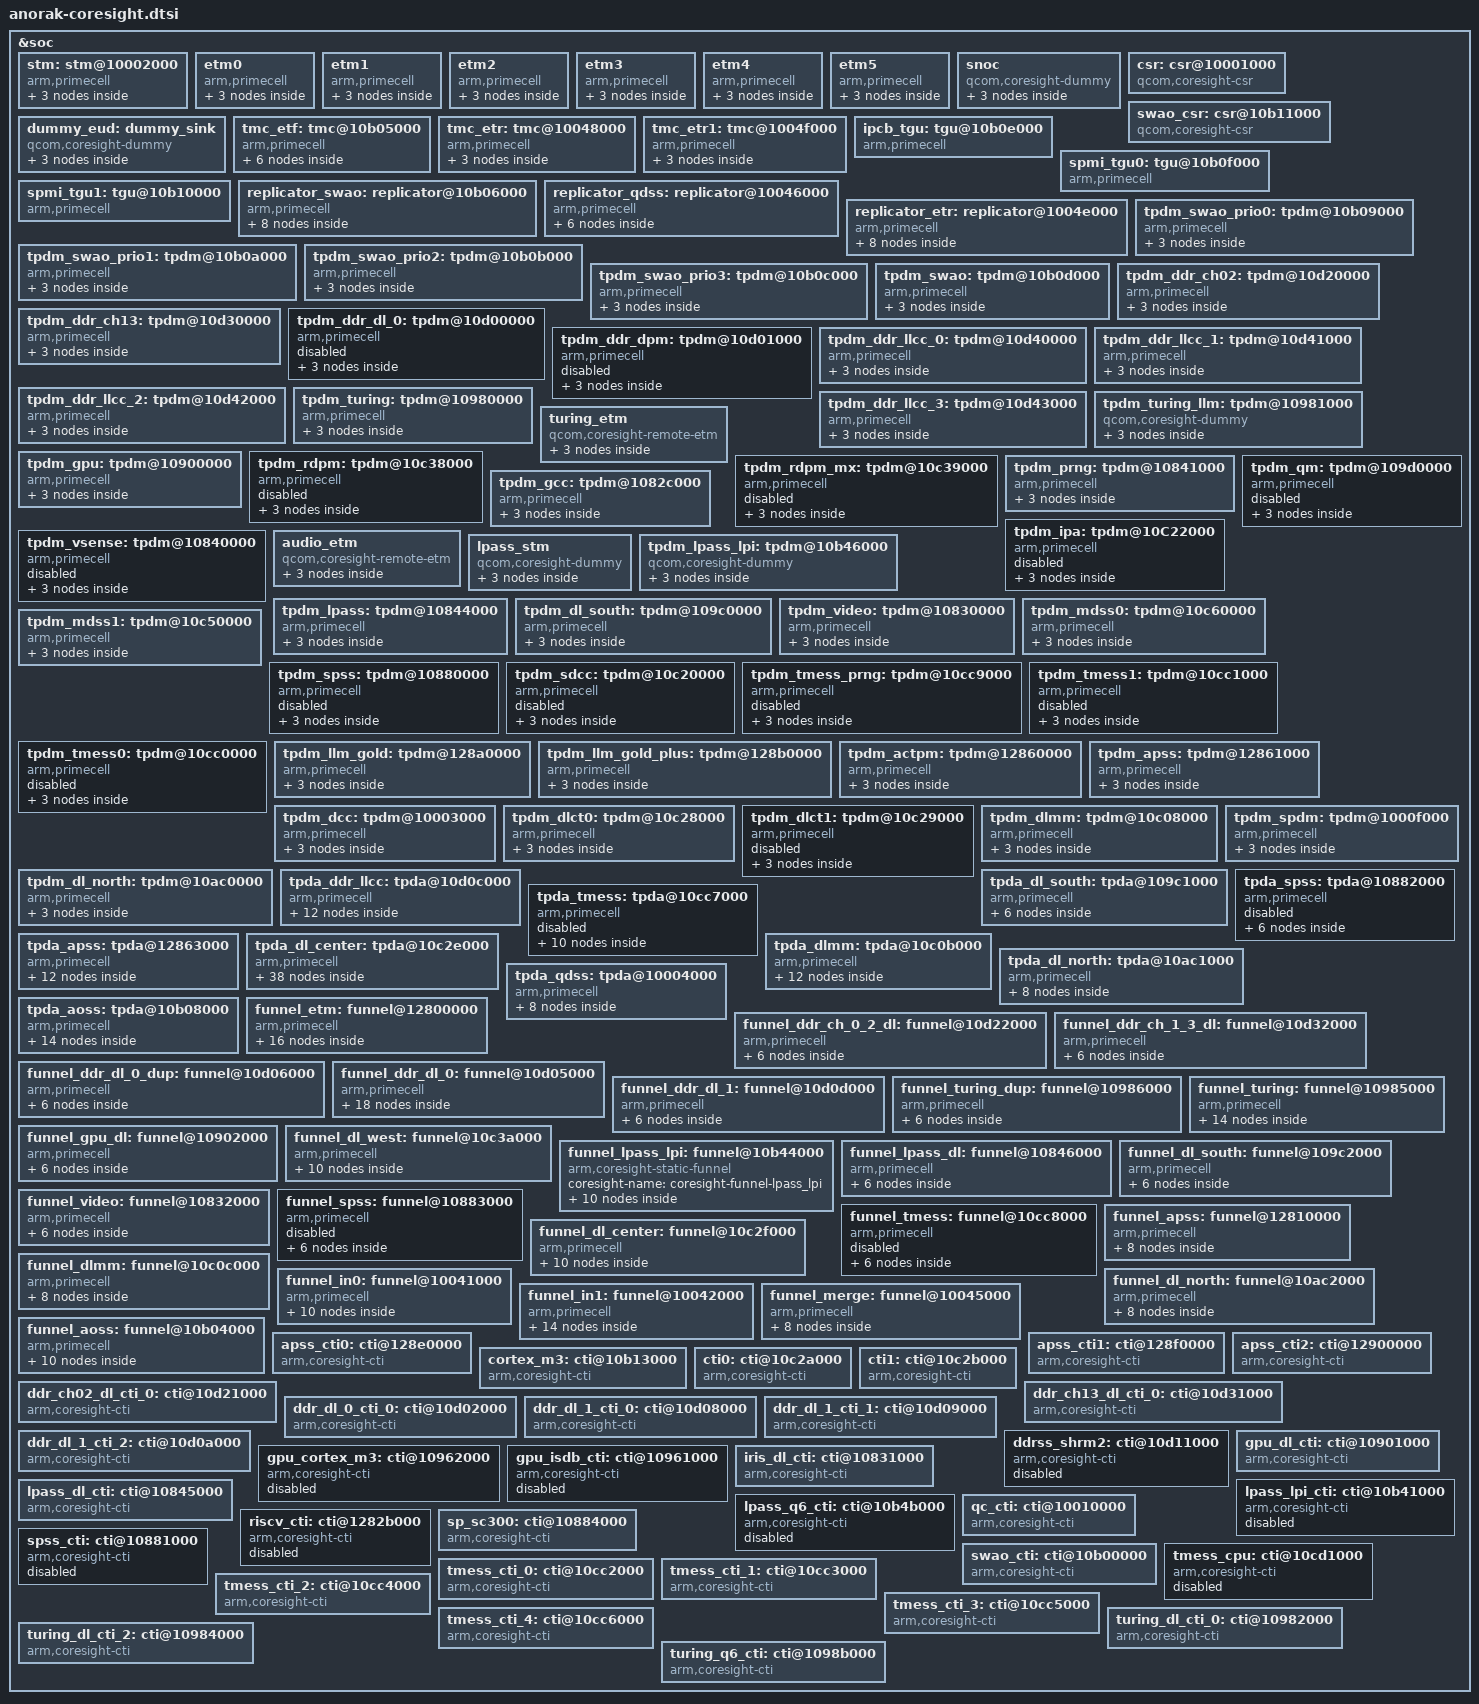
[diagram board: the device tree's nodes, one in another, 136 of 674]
&soc {

	stm: stm@10002000 {
		compatible = "arm,primecell";
		arm,primecell-periphid = <0x000bb962>;
		reg = <0x10002000 0x1000>,
			<0x16280000 0x180000>;
		reg-names = "stm-base", "stm-stimulus-base";

		atid = <16>;
		coresight-name = "coresight-stm";

		clocks = <&aoss_qmp>;
		clock-names = "apb_pclk";

		out-ports {
			port {
				stm_out_funnel_in0: endpoint {
					remote-endpoint =
					<&funnel_in0_in_stm>;
				};
			};
		};
	};

	etm0 {
		compatible = "arm,primecell";
		arm,primecell-periphid = <0x000bb95d>;
		reg = <0x12040000 0x1000>;
		cpu = <&CPU0>;

		coresight-name = "coresight-etm0";
		qcom,skip-power-up;

		clocks = <&aoss_qmp>;
		clock-names = "apb_pclk";
		atid = <1>;
		out-ports {
			port {
				ete0_out_funnel_ete: endpoint {
				remote-endpoint = <&funnel_ete_in_ete0>;
				};
			};
		};
	};

	etm1 {
		compatible = "arm,primecell";
		arm,primecell-periphid = <0x000bb95d>;
		reg = <0x12140000 0x1000>;
		cpu = <&CPU1>;

		coresight-name = "coresight-etm1";
		qcom,skip-power-up;

		clocks = <&aoss_qmp>;
		clock-names = "apb_pclk";
		atid = <2>;
		out-ports {
			port {
				ete1_out_funnel_ete: endpoint {
				remote-endpoint = <&funnel_ete_in_ete1>;
				};
			};
		};
	};

	etm2 {
		compatible = "arm,primecell";
		arm,primecell-periphid = <0x000bb95d>;
		reg = <0x12240000 0x1000>;
		cpu = <&CPU2>;

		coresight-name = "coresight-etm2";
		qcom,skip-power-up;

		clocks = <&aoss_qmp>;
		clock-names = "apb_pclk";
		atid = <3>;
		out-ports {
			port {
				ete2_out_funnel_ete: endpoint {
				remote-endpoint = <&funnel_ete_in_ete2>;
				};
			};
		};
	};

	etm3 {
		compatible = "arm,primecell";
		arm,primecell-periphid = <0x000bb95d>;
		reg = <0x12340000 0x1000>;
		cpu = <&CPU3>;

		coresight-name = "coresight-etm3";
		qcom,skip-power-up;

		clocks = <&aoss_qmp>;
		clock-names = "apb_pclk";
		atid = <4>;
		out-ports {
			port {
				ete3_out_funnel_ete: endpoint {
				remote-endpoint = <&funnel_ete_in_ete3>;
				};
			};
		};
	};

	etm4 {
		compatible = "arm,primecell";
		arm,primecell-periphid = <0x000bb95d>;
		reg = <0x12440000 0x1000>;
		cpu = <&CPU4>;

		coresight-name = "coresight-etm4";
		qcom,skip-power-up;

		clocks = <&aoss_qmp>;
		clock-names = "apb_pclk";
		atid = <5>;
		out-ports {
			port {
				ete4_out_funnel_ete: endpoint {
				remote-endpoint = <&funnel_ete_in_ete4>;
				};
			};
		};
	};

	etm5 {
		compatible = "arm,primecell";
		arm,primecell-periphid = <0x000bb95d>;
		reg = <0x12540000 0x1000>;
		cpu = <&CPU5>;

		coresight-name = "coresight-etm5";
		qcom,skip-power-up;

		clocks = <&aoss_qmp>;
		clock-names = "apb_pclk";
		atid = <6>;
		out-ports {
			port {
				ete5_out_funnel_ete: endpoint {
				remote-endpoint = <&funnel_ete_in_ete5>;
				};
			};
		};
	};

	snoc: snoc {
		compatible = "qcom,coresight-dummy";
		coresight-name = "coresight-snoc";
		qcom,dummy-source;

		atid = <125>;
		out-ports {
			port {
				snoc_out_funnel_in0: endpoint {
					remote-endpoint =
					<&funnel_in0_in_snoc>;
				};
			};
		};
	};

	csr: csr@10001000 {
		compatible = "qcom,coresight-csr";
		reg = <0x10001000 0x1000>;
		reg-names = "csr-base";

		coresight-name = "coresight-csr";
		qcom,usb-bam-support;
		qcom,hwctrl-set-support;
		qcom,set-byte-cntr-support;

		qcom,blk-size = <1>;
	};

	swao_csr: csr@10b11000 {
		compatible = "qcom,coresight-csr";

		reg = <0x10b11000 0x1000>,
		      <0x10b110f8 0x50>;
		reg-names = "csr-base", "msr-base";

		coresight-name = "coresight-swao-csr";
		qcom,timestamp-support;
		qcom,msr-support;
		qcom,blk-size = <1>;

		clocks = <&aoss_qmp>;
		clock-names = "apb_pclk";
	};

	dummy_eud: dummy_sink {
		compatible = "qcom,coresight-dummy";

		coresight-name = "coresight-eud";

		qcom,dummy-sink;
		in-ports {
			port {
				eud_in_replicator_swao: endpoint {
					remote-endpoint =
						<&replicator_swao_out_eud>;
				};
			};
		};
	};

	tmc_etf: tmc@10b05000 {
		compatible = "arm,primecell";
		arm,primecell-periphid = <0x000bb961>;
		reg = <0x10b05000 0x1000>;
		reg-names = "tmc-base";

		coresight-name = "coresight-tmc-etf";

		clocks = <&aoss_qmp>;
		clock-names = "apb_pclk";

		in-ports {
			port {
				tmc_etf_in_funnel_aoss: endpoint {
					remote-endpoint =
					<&funnel_aoss_out_tmc_etf>;
				};
			};
		};

		out-ports {
			port {
				tmc_etf_out_replicator_swao: endpoint {
					remote-endpoint =
					<&replicator_swao_in_tmc_etf>;
				};
			};
		};
	};

	tmc_etr: tmc@10048000 {
		compatible = "arm,primecell";
		arm,primecell-periphid = <0x000bb961>;
		reg = <0x10048000 0x1000>,
			<0x10064000 0x16000>;
		reg-names = "tmc-base", "bam-base";

		qcom,iommu-dma = "bypass";
		iommus = <&apps_smmu 0x04c0 0>,
			<&apps_smmu 0x04a0 0>;

		qcom,iommu-dma-addr-pool = <0x0 0xffc00000>;

		qcom,sw-usb;
		dma-coherent;
		coresight-name = "coresight-tmc-etr";

		coresight-csr = <&csr>;
		csr-atid-offset = <0xf8>;
		csr-irqctrl-offset = <0x6c>;
		byte-cntr-name = "byte-cntr";
		byte-cntr-class-name = "coresight-tmc-etr-stream";

		interrupts = <GIC_SPI 270 IRQ_TYPE_EDGE_RISING>;
		interrupt-names = "byte-cntr-irq";

		arm,scatter-gather;
		clocks = <&aoss_qmp>;
		clock-names = "apb_pclk";

		in-ports {
			port {
				tmc_etr_in_replicator_etr: endpoint {
					remote-endpoint =
					<&replicator_etr_out_tmc_etr>;
				};
			};
		};
	};

	tmc_etr1: tmc@1004f000 {
		compatible = "arm,primecell";
		arm,primecell-periphid = <0x000bb961>;
		reg = <0x1004f000 0x1000>;
		reg-names = "tmc-base";

		coresight-name = "coresight-tmc-etr1";

		iommus = <&apps_smmu 0x04e0 0>;
		qcom,iommu-dma-addr-pool = <0x0 0xffc00000>;

		dma-coherent;
		coresight-csr = <&csr>;
		csr-atid-offset = <0x108>;
		csr-irqctrl-offset = <0x70>;
		byte-cntr-name = "byte-cntr1";
		byte-cntr-class-name = "coresight-tmc-etr1-stream";

		interrupts = <GIC_SPI 269 IRQ_TYPE_EDGE_RISING>;
		interrupt-names = "byte-cntr-irq";

		arm,scatter-gather;
		clocks = <&aoss_qmp>;
		clock-names = "apb_pclk";

		in-ports {
			port {
				tmc_etr1_in_replicator_etr: endpoint {
					remote-endpoint =
					<&replicator_etr_out_tmc_etr1>;
				};
			};
		};
	};

	ipcb_tgu: tgu@10b0e000 {
		compatible = "arm,primecell";
		arm,primecell-periphid = <0x000bb999>;

		reg = <0x10b0e000 0x1000>;
		reg-names = "tgu-base";

		tgu-steps = <3>;
		tgu-conditions = <4>;
		tgu-regs = <4>;
		tgu-timer-counters = <8>;

		coresight-name = "coresight-tgu-ipcb";
		clocks = <&aoss_qmp>;
		clock-names = "apb_pclk";
	};

	spmi_tgu0: tgu@10b0f000 {
		compatible = "arm,primecell";
		arm,primecell-periphid = <0x000bb999>;

		reg = <0x10b0f000 0x1000>;
		reg-names = "tgu-base";

		tgu-steps = <3>;
		tgu-conditions = <4>;
		tgu-regs = <9>;
		tgu-timer-counters = <8>;

		coresight-name = "coresight-tgu-spmi0";
		clocks = <&aoss_qmp>;
		clock-names = "apb_pclk";
	};

	spmi_tgu1: tgu@10b10000 {
		compatible = "arm,primecell";
		arm,primecell-periphid = <0x000bb999>;

		reg = <0x10b10000 0x1000>;
		reg-names = "tgu-base";

		tgu-steps = <3>;
		tgu-conditions = <4>;
		tgu-regs = <9>;
		tgu-timer-counters = <8>;

		coresight-name = "coresight-tgu-spmi1";
		clocks = <&aoss_qmp>;
		clock-names = "apb_pclk";
	};

	replicator_swao: replicator@10b06000 {
		compatible = "arm,primecell";
		arm,primecell-periphid = <0x000bb909>;
		reg = <0x10b06000 0x1000>;
		reg-names = "replicator-base";

		coresight-name = "coresight-replicator-swao";

		clocks = <&aoss_qmp>;
		clock-names = "apb_pclk";

		in-ports {
			port {
				replicator_swao_in_tmc_etf: endpoint {
					remote-endpoint =
					<&tmc_etf_out_replicator_swao>;
				};
			};
		};

		out-ports {
			#address-cells = <1>;
			#size-cells = <0>;

			port@0 {
				reg = <0>;
				replicator_swao_out_replicator_qdss: endpoint {
					remote-endpoint =
					<&replicator_qdss_in_replicator_swao>;
				};
			};

			port@1 {
				reg = <1>;
				replicator_swao_out_eud: endpoint {
					remote-endpoint =
					  <&eud_in_replicator_swao>;
				};
			};
		};
	};

	replicator_qdss: replicator@10046000 {
		compatible = "arm,primecell";
		arm,primecell-periphid = <0x000bb909>;
		reg = <0x10046000 0x1000>;
		reg-names = "replicator-base";

		coresight-name = "coresight-replicator-qdss";

		clocks = <&aoss_qmp>;
		clock-names = "apb_pclk";

		in-ports {
			port {
				replicator_qdss_in_replicator_swao: endpoint {
					remote-endpoint =
					<&replicator_swao_out_replicator_qdss>;
				};
			};
		};

		out-ports {

			port@0 {
				replicator_qdss_out_replicator_etr: endpoint {
					remote-endpoint =
					<&replicator_etr_in_replicator_qdss>;
				};
			};
		};
	};

	replicator_etr: replicator@1004e000 {
		compatible = "arm,primecell";
		arm,primecell-periphid = <0x000bb909>;
		reg = <0x1004e000 0x1000>;
		reg-names = "replicator-base";

		coresight-name = "coresight-replicator-etr";

		clocks = <&aoss_qmp>;
		clock-names = "apb_pclk";

		in-ports {
			port {
				replicator_etr_in_replicator_qdss: endpoint {
					remote-endpoint =
					<&replicator_qdss_out_replicator_etr>;
				};
			};
		};

		out-ports {
			#address-cells = <1>;
			#size-cells = <0>;

			port@0 {
				reg = <0>;
				replicator_etr_out_tmc_etr: endpoint {
					remote-endpoint =
					<&tmc_etr_in_replicator_etr>;
				};
			};

			port@1 {
				reg = <1>;
				replicator_etr_out_tmc_etr1: endpoint {
					remote-endpoint =
					<&tmc_etr1_in_replicator_etr>;
				};
			};
		};
	};

	tpdm_swao_prio0: tpdm@10b09000 {
		compatible = "arm,primecell";
		arm,primecell-periphid = <0x000bb968>;
		reg = <0x10b09000 0x1000>;
		reg-names = "tpdm-base";

		coresight-name = "coresight-tpdm-swao-prio-0";
		atid = <71>;
		clocks = <&aoss_qmp>;
		clock-names = "apb_pclk";

		out-ports {
			port {
				tpdm_swao_prio0_out_tpda_aoss: endpoint {
					remote-endpoint =
					<&tpda_aoss_in_tpdm_swao_prio0>;
				};
			};
		};
	};

	tpdm_swao_prio1: tpdm@10b0a000 {
		compatible = "arm,primecell";
		arm,primecell-periphid = <0x000bb968>;
		reg = <0x10b0a000 0x1000>;
		reg-names = "tpdm-base";

		coresight-name = "coresight-tpdm-swao-prio-1";
		atid = <71>;
		clocks = <&aoss_qmp>;
		clock-names = "apb_pclk";

		out-ports {
			port {
				tpdm_swao_prio1_out_tpda_aoss: endpoint {
					remote-endpoint =
					<&tpda_aoss_in_tpdm_swao_prio1>;
				};
			};
		};
	};

	tpdm_swao_prio2: tpdm@10b0b000 {
		compatible = "arm,primecell";
		arm,primecell-periphid = <0x000bb968>;
		reg = <0x10b0b000 0x1000>;
		reg-names = "tpdm-base";

		coresight-name = "coresight-tpdm-swao-prio-2";
		atid = <71>;
		clocks = <&aoss_qmp>;
		clock-names = "apb_pclk";

		out-ports {
			port {
				tpdm_swao_prio2_out_tpda_aoss: endpoint {
					remote-endpoint =
					<&tpda_aoss_in_tpdm_swao_prio2>;
				};
			};
		};
	};

	tpdm_swao_prio3: tpdm@10b0c000 {
		compatible = "arm,primecell";
		arm,primecell-periphid = <0x000bb968>;
		reg = <0x10b0c000 0x1000>;
		reg-names = "tpdm-base";

		coresight-name = "coresight-tpdm-swao-prio-3";
		atid = <71>;
		clocks = <&aoss_qmp>;
		clock-names = "apb_pclk";

		out-ports {
			port {
				tpdm_swao_prio3_out_tpda_aoss: endpoint {
					remote-endpoint =
					<&tpda_aoss_in_tpdm_swao_prio3>;
				};
			};
		};
	};

	tpdm_swao: tpdm@10b0d000 {
		compatible = "arm,primecell";
		arm,primecell-periphid = <0x000bb968>;
		reg = <0x10b0d000 0x1000>;
		reg-names = "tpdm-base";

		coresight-name = "coresight-tpdm-swao";
		atid = <71>;
		clocks = <&aoss_qmp>;
		clock-names = "apb_pclk";

		out-ports {
			port {
				tpdm_swao_out_tpda_aoss: endpoint {
					remote-endpoint =
					<&tpda_aoss_in_tpdm_swao>;
				};
			};
		};
	};

	tpdm_ddr_ch02: tpdm@10d20000 {
		compatible = "arm,primecell";
		arm,primecell-periphid = <0x000bb968>;
		reg = <0x10d20000 0x1000>;
		reg-names = "tpdm-base";

		coresight-name = "coresight-tpdm-ddr-ch02";
		atid = <78>;
		clocks = <&aoss_qmp>;
		clock-names = "apb_pclk";

		out-ports {
			port {
				tpdm_ddr_ch_0_2_out_funnel_ddr_ch_0_2_dl: endpoint {
					remote-endpoint =
					<&funnel_ddr_ch_0_2_dl_in_tpdm_ddr_ch_0_2>;
				};
			};
		};
	};

	tpdm_ddr_ch13: tpdm@10d30000 {
		compatible = "arm,primecell";
		arm,primecell-periphid = <0x000bb968>;
		reg = <0x10d30000 0x1000>;
		reg-names = "tpdm-base";

		coresight-name = "coresight-tpdm-ddr-ch13";
		atid = <78>;
		clocks = <&aoss_qmp>;
		clock-names = "apb_pclk";

		out-ports {
			port {
				tpdm_ddr_ch_1_3_out_funnel_ddr_ch_1_3_dl: endpoint {
					remote-endpoint =
					<&funnel_ddr_ch_1_3_dl_in_tpdm_ddr_ch_1_3>;
				};
			};
		};
	};

	tpdm_ddr_dl_0: tpdm@10d00000 {
		compatible = "arm,primecell";
		arm,primecell-periphid = <0x000bb968>;
		reg = <0x10d00000 0x1000>;
		reg-names = "tpdm-base";

		coresight-name = "coresight-tpdm-ddr-dl_0";
		atid = <78>;
		clocks = <&aoss_qmp>;
		clock-names = "apb_pclk";

		status = "disabled";
		qcom,cmb-msr-skip;
		out-ports {
			port {
				tpdm_ddr_dl_0_out_funnel_ddr_dl_0: endpoint {
					remote-endpoint =
					<&funnel_ddr_dl_0_in_tpdm_ddr_dl_0>;
				};
			};
		};
	};

	tpdm_ddr_dpm: tpdm@10d01000 {
		compatible = "arm,primecell";
		arm,primecell-periphid = <0x000bb968>;
		reg = <0x10d01000 0x1000>;
		reg-names = "tpdm-base";

		coresight-name = "coresight-tpdm-ddr-dpm";
		atid = <78>;
		clocks = <&aoss_qmp>;
		clock-names = "apb_pclk";

		status = "disabled";
		qcom,cmb-msr-skip;
		out-ports {
			port {
				tpdm_ddr_dpm_out_funnel_ddr_dl_0: endpoint {
					remote-endpoint =
					<&funnel_ddr_dl_0_in_tpdm_ddr_dpm>;
				};
			};
		};
	};

	tpdm_ddr_llcc_0: tpdm@10d40000 {
		compatible = "arm,primecell";
		arm,primecell-periphid = <0x000bb968>;
		reg = <0x10d40000 0x1000>;
		reg-names = "tpdm-base";

		coresight-name = "coresight-tpdm-ddr-llcc_0";
		atid = <99>;
		clocks = <&aoss_qmp>;
		clock-names = "apb_pclk";

		out-ports {
			port {
				tpdm_ddr_llcc_0_out_tpda_ddr_llcc: endpoint {
					remote-endpoint =
					<&tpda_ddr_llcc_in_tpdm_ddr_llcc_0>;
				};
			};
		};
	};

	tpdm_ddr_llcc_1: tpdm@10d41000 {
		compatible = "arm,primecell";
		arm,primecell-periphid = <0x000bb968>;
		reg = <0x10d41000 0x1000>;
		reg-names = "tpdm-base";

		coresight-name = "coresight-tpdm-ddr-llcc_1";
		atid = <99>;
		clocks = <&aoss_qmp>;
		clock-names = "apb_pclk";

		out-ports {
			port {
				tpdm_ddr_llcc_1_out_tpda_ddr_llcc: endpoint {
					remote-endpoint =
					<&tpda_ddr_llcc_in_tpdm_ddr_llcc_1>;
				};
			};
		};
	};

	tpdm_ddr_llcc_2: tpdm@10d42000 {
		compatible = "arm,primecell";
		arm,primecell-periphid = <0x000bb968>;
		reg = <0x10d42000 0x1000>;
		reg-names = "tpdm-base";

		coresight-name = "coresight-tpdm-ddr-llcc_2";
		atid = <99>;
		clocks = <&aoss_qmp>;
		clock-names = "apb_pclk";

		out-ports {
			port {
				tpdm_ddr_llcc_2_out_tpda_ddr_llcc: endpoint {
					remote-endpoint =
					<&tpda_ddr_llcc_in_tpdm_ddr_llcc_2>;
				};
			};
		};
	};

	tpdm_ddr_llcc_3: tpdm@10d43000 {
		compatible = "arm,primecell";
		arm,primecell-periphid = <0x000bb968>;
		reg = <0x10d43000 0x1000>;
		reg-names = "tpdm-base";

		coresight-name = "coresight-tpdm-ddr-llcc_3";
		atid = <99>;
		clocks = <&aoss_qmp>;
		clock-names = "apb_pclk";

		out-ports {
			port {
				tpdm_ddr_llcc_3_out_tpda_ddr_llcc: endpoint {
					remote-endpoint =
					<&tpda_ddr_llcc_in_tpdm_ddr_llcc_3>;
				};
			};
		};
	};

	tpdm_turing: tpdm@10980000 {
		compatible = "arm,primecell";
		arm,primecell-periphid = <0x000bb968>;
		reg = <0x10980000 0x1000>;
		reg-names = "tpdm-base";

		coresight-name = "coresight-tpdm-turing";
		atid = <78>;
		clocks = <&aoss_qmp>;
		clock-names = "apb_pclk";

		out-ports {
			port {
				tpdm_turing_out_funnel_turing: endpoint {
					remote-endpoint =
					<&funnel_turing_in_tpdm_turing>;
				};
			};
		};
	};

	tpdm_turing_llm: tpdm@10981000 {
		compatible = "qcom,coresight-dummy";
		coresight-name = "coresight-tpdm-turing-llm";
		qcom,dummy-source;

		out-ports {
			port {
				tpdm_turing_llm_out_funnel_turing: endpoint {
					remote-endpoint =
					<&funnel_turing_in_tpdm_turing_llm>;
				};
			};
		};
	};

	turing_etm {
		compatible = "qcom,coresight-remote-etm";

		coresight-name = "coresight-turing-etm0";
		qcom,inst-id = <13>;

		atid = <38 39>;

		out-ports {
			port {
				turing_etm_out_funnel_turing_dup: endpoint {
					remote-endpoint =
						<&funnel_turing_dup_in_turing_etm>;
				};
			};
		};
	};

	tpdm_gpu: tpdm@10900000 {
		compatible = "arm,primecell";
		arm,primecell-periphid = <0x000bb968>;
		reg = <0x10900000 0x1000>;
		reg-names = "tpdm-base";

		coresight-name = "coresight-tpdm-gpu";
		atid = <78>;
		clocks = <&aoss_qmp>;
		clock-names = "apb_pclk";

		out-ports {
			port {
				tpdm_gpu_out_funnel_gpu_dl: endpoint {
					remote-endpoint =
					<&funnel_gpu_dl_in_tpdm_gpu>;
				};
			};
		};
	};

	tpdm_rdpm: tpdm@10c38000 {
		compatible = "arm,primecell";
		arm,primecell-periphid = <0x000bb968>;
		reg = <0x10c38000 0x1000>;
		reg-names = "tpdm-base";

		coresight-name = "coresight-tpdm-rdpm";
		atid = <78>;
		clocks = <&aoss_qmp>;
		clock-names = "apb_pclk";

		status = "disabled";
		out-ports {
			port {
				tpdm_rdpm_out_funnel_dl_west: endpoint {
					remote-endpoint =
					<&funnel_dl_west_in_tpdm_rdpm>;
				};
			};
		};
	};

	tpdm_rdpm_mx: tpdm@10c39000 {
		compatible = "arm,primecell";
		arm,primecell-periphid = <0x000bb968>;
		reg = <0x10c39000 0x1000>;
		reg-names = "tpdm-base";

		coresight-name = "coresight-tpdm-rdpm-mx";
		atid = <78>;
		clocks = <&aoss_qmp>;
		clock-names = "apb_pclk";
		qcom,cmb-msr-skip;

		status = "disabled";
		out-ports {
			port {
				tpdm_rdpm_mx_out_funnel_dl_west: endpoint {
					remote-endpoint =
					<&funnel_dl_west_in_tpdm_rdpm_mx>;
				};
			};
		};
	};

	tpdm_prng: tpdm@10841000 {
		compatible = "arm,primecell";
		arm,primecell-periphid = <0x000bb968>;
		reg = <0x10841000 0x1000>;
		reg-names = "tpdm-base";

		coresight-name = "coresight-tpdm-prng";
		atid = <78>;
		clocks = <&aoss_qmp>;
		clock-names = "apb_pclk";

		out-ports {
			port {
				tpdm_prng_out_tpda_dl_center: endpoint {
					remote-endpoint =
					<&tpda_dl_center_in_tpdm_prng>;
				};
			};
		};
	};

	tpdm_qm: tpdm@109d0000 {
		compatible = "arm,primecell";
		arm,primecell-periphid = <0x000bb968>;
		reg = <0x109d0000 0x1000>;
		reg-names = "tpdm-base";

		coresight-name = "coresight-tpdm-qm";
		atid = <78>;
		clocks = <&aoss_qmp>;
		clock-names = "apb_pclk";

		status = "disabled";
		out-ports {
			port {
				tpdm_qm_out_tpda_dl_center: endpoint {
					remote-endpoint =
					<&tpda_dl_center_in_tpdm_qm>;
				};
			};
		};
	};

	tpdm_gcc: tpdm@1082c000 {
		compatible = "arm,primecell";
		arm,primecell-periphid = <0x000bb968>;
		reg = <0x1082c000 0x1000>;
		reg-names = "tpdm-base";

		coresight-name = "coresight-tpdm-gcc";
		atid = <78>;
		clocks = <&aoss_qmp>;
		clock-names = "apb_pclk";

		out-ports {
			port {
				tpdm_gcc_out_tpda_dl_center: endpoint {
					remote-endpoint =
					<&tpda_dl_center_in_tpdm_gcc>;
				};
			};
		};
	};

	tpdm_vsense: tpdm@10840000 {
		compatible = "arm,primecell";
		arm,primecell-periphid = <0x000bb968>;
		reg = <0x10840000 0x1000>;
		reg-names = "tpdm-base";

		coresight-name = "coresight-tpdm-vsense";
		atid = <78>;
		clocks = <&aoss_qmp>;
		clock-names = "apb_pclk";

		status = "disabled";
		out-ports {
			port {
				tpdm_vsense_out_tpda_dl_center: endpoint {
					remote-endpoint =
					<&tpda_dl_center_in_tpdm_vsense>;
				};
			};
		};
	};

	tpdm_ipa: tpdm@10C22000 {
		compatible = "arm,primecell";
		arm,primecell-periphid = <0x000bb968>;
		reg = <0x10C22000 0x1000>;
		reg-names = "tpdm-base";

		coresight-name = "coresight-tpdm-ipa";
		atid = <78>;
		clocks = <&aoss_qmp>;
		clock-names = "apb_pclk";
		qcom,cmb-msr-skip;

		status = "disabled";
		out-ports {
			port {
				tpdm_ipa_out_tpda_dl_center: endpoint {
					remote-endpoint =
					<&tpda_dl_center_in_tpdm_ipa>;
				};
			};
		};
	};

	audio_etm {
		compatible = "qcom,coresight-remote-etm";

		coresight-name = "coresight-audio-etm0";
		qcom,inst-id = <5>;

		atid = <40 41>;

		out-ports {
			port {
				audio_etm_out_funnel_lpass_lpi: endpoint {
					remote-endpoint =
						<&funnel_lpass_lpi_in_audio_etm>;
				};
			};
		};
	};

	lpass_stm: lpass_stm {
		compatible = "qcom,coresight-dummy";
		coresight-name = "coresight-lpass-stm";
		qcom,dummy-source;

		atid = <25>;

		out-ports {
			port {
				lpass_stm_out_funnel_lpass_lpi: endpoint {
					remote-endpoint =
					<&funnel_lpass_lpi_in_lpass_stm>;
				};
			};
		};
	};

	tpdm_lpass_lpi: tpdm@10b46000 {
		compatible = "qcom,coresight-dummy";
		coresight-name = "coresight-tpdm-lpass-lpi";
		qcom,dummy-source;

		atid = <26>;

		out-ports {
			port {
				tpdm_lpass_lpi_out_funnel_lpass_lpi: endpoint {
					remote-endpoint =
					<&funnel_lpass_lpi_in_tpdm_lpass_lpi>;
				};
			};
		};
	};

	tpdm_lpass: tpdm@10844000 {
		compatible = "arm,primecell";
		arm,primecell-periphid = <0x000bb968>;
		reg = <0x10844000 0x1000>;
		reg-names = "tpdm-base";

		coresight-name = "coresight-tpdm-lpass";
		atid = <78>;
		clocks = <&aoss_qmp>;
		clock-names = "apb_pclk";

		out-ports {
			port {
				tpdm_lpass_out_funnel_lpass_dl: endpoint {
					remote-endpoint =
					<&funnel_lpass_dl_in_tpdm_lpass>;
				};
			};
		};
	};

	tpdm_dl_south: tpdm@109c0000 {
		compatible = "arm,primecell";
		arm,primecell-periphid = <0x000bb968>;
		reg = <0x109c0000 0x1000>;
		reg-names = "tpdm-base";

		coresight-name = "coresight-tpdm-dl-south";
		atid = <75>;
		clocks = <&aoss_qmp>;
		clock-names = "apb_pclk";

		out-ports {
			port {
				tpdm_dl_south_out_tpda_dl_south: endpoint {
					remote-endpoint =
					<&tpda_dl_south_in_tpdm_dl_south>;
				};
			};
		};
	};

	tpdm_video: tpdm@10830000 {
		compatible = "arm,primecell";
		arm,primecell-periphid = <0x000bb968>;
		reg = <0x10830000 0x1000>;
		reg-names = "tpdm-base";

		coresight-name = "coresight-tpdm-video";
		atid = <81>;
		clocks = <&aoss_qmp>;
		clock-names = "apb_pclk";

		out-ports {
			port {
				tpdm_video_out_funnel_video: endpoint {
					remote-endpoint =
					<&funnel_video_in_tpdm_video>;
				};
			};
		};
	};

	tpdm_mdss0: tpdm@10c60000 {
		compatible = "arm,primecell";
		arm,primecell-periphid = <0x000bb968>;
		reg = <0x10c60000 0x1000>;
		reg-names = "tpdm-base";

		coresight-name = "coresight-tpdm-mdss0";
		atid = <81>;
		clocks = <&aoss_qmp>;
		clock-names = "apb_pclk";

		out-ports {
			port {
				tpdm_mdss0_out_tpda_dlmm: endpoint {
					remote-endpoint =
					<&tpda_dlmm_in_tpdm_mdss0>;
				};
			};
		};
	};

	tpdm_mdss1: tpdm@10c50000 {
		compatible = "arm,primecell";
		arm,primecell-periphid = <0x000bb968>;
		reg = <0x10c50000 0x1000>;
		reg-names = "tpdm-base";

		coresight-name = "coresight-tpdm-mdss1";
		atid = <81>;
		clocks = <&aoss_qmp>;
		clock-names = "apb_pclk";

		out-ports {
			port {
				tpdm_mdss1_out_tpda_dlmm: endpoint {
					remote-endpoint =
					<&tpda_dlmm_in_tpdm_mdss1>;
				};
			};
		};
	};

	tpdm_spss: tpdm@10880000 {
		compatible = "arm,primecell";
		arm,primecell-periphid = <0x000bb968>;
		reg = <0x10880000 0x1000>;
		reg-names = "tpdm-base";

		coresight-name = "coresight-tpdm-spss";

		atid = <70>;
		clocks = <&aoss_qmp>;
		clock-names = "apb_pclk";
		status = "disabled";

		out-ports {
			port {
				tpdm_spss_out_tpda_spss: endpoint {
					remote-endpoint =
					<&tpda_spss_in_tpdm_spss>;
				};
			};
		};
	};

	tpdm_sdcc: tpdm@10c20000 {
		compatible = "arm,primecell";
		arm,primecell-periphid = <0x000bb968>;
		reg = <0x10c20000 0x1000>;
		reg-names = "tpdm-base";

		coresight-name = "coresight-tpdm-sdcc";
		atid = <97>;
		clocks = <&aoss_qmp>;
		clock-names = "apb_pclk";
		qcom,cmb-msr-skip;

		status = "disabled";
		out-ports {
			port {
				tpdm_sdcc_out_tpda_dl_north: endpoint {
					remote-endpoint =
					<&tpda_dl_north_in_tpdm_sdcc>;
				};
			};
		};
	};

	tpdm_tmess_prng: tpdm@10cc9000 {
		compatible = "arm,primecell";
		arm,primecell-periphid = <0x000bb968>;
		reg = <0x10cc9000 0x1000>;
		reg-names = "tpdm-base";

		coresight-name = "coresight-tpdm-tmess-prng";
		atid = <85>;
		clocks = <&aoss_qmp>;
		clock-names = "apb_pclk";

		status = "disabled";
		out-ports {
			port {
				tpdm_tmess_prng_out_tpda_tmess: endpoint {
					remote-endpoint =
					<&tpda_tmess_in_tpdm_tmess_prng>;
				};
			};
		};
	};

	tpdm_tmess1: tpdm@10cc1000 {
		compatible = "arm,primecell";
		arm,primecell-periphid = <0x000bb968>;
		reg = <0x10cc1000 0x1000>;
		reg-names = "tpdm-base";

		coresight-name = "coresight-tpdm-tmess1";
		atid = <85>;
		clocks = <&aoss_qmp>;
		clock-names = "apb_pclk";

		status = "disabled";
		out-ports {
			port {
				tpdm_tmess1_out_tpda_tmess: endpoint {
					remote-endpoint =
					<&tpda_tmess_in_tpdm_tmess1>;
				};
			};
		};
	};

	tpdm_tmess0: tpdm@10cc0000 {
		compatible = "arm,primecell";
		arm,primecell-periphid = <0x000bb968>;
		reg = <0x10cc0000 0x1000>;
		reg-names = "tpdm-base";

		coresight-name = "coresight-tpdm-tmess0";
		atid = <85>;
		clocks = <&aoss_qmp>;
		clock-names = "apb_pclk";

		status = "disabled";
		out-ports {
			port {
				tpdm_tmess0_out_tpda_tmess: endpoint {
					remote-endpoint =
					<&tpda_tmess_in_tpdm_tmess0>;
				};
			};
		};
	};

	tpdm_llm_gold: tpdm@128a0000 {
		compatible = "arm,primecell";
		arm,primecell-periphid = <0x000bb968>;
		reg = <0x128a0000 0x1000>;
		reg-names = "tpdm-base";

		coresight-name = "coresight-tpdm-llm-gold";
		atid = <66>;
		clocks = <&aoss_qmp>;
		clock-names = "apb_pclk";

		out-ports {
			port {
				tpdm_llm_gold_out_tpda_apss: endpoint {
					remote-endpoint =
					<&tpda_apss_in_tpdm_llm_gold>;
				};
			};
		};
	};

	tpdm_llm_gold_plus: tpdm@128b0000 {
		compatible = "arm,primecell";
		arm,primecell-periphid = <0x000bb968>;
		reg = <0x128b0000 0x1000>;
		reg-names = "tpdm-base";

		coresight-name = "coresight-tpdm-llm-gold-plus";
		atid = <66>;
		clocks = <&aoss_qmp>;
		clock-names = "apb_pclk";

		out-ports {
			port {
				tpdm_llm_gold_plus_out_tpda_apss: endpoint {
					remote-endpoint =
					<&tpda_apss_in_tpdm_llm_gold_plus>;
				};
			};
		};
	};

	tpdm_actpm: tpdm@12860000 {
		compatible = "arm,primecell";
		arm,primecell-periphid = <0x000bb968>;
		reg = <0x12860000 0x1000>;
		reg-names = "tpdm-base";

		coresight-name = "coresight-tpdm-actpm";
		atid = <66>;
		clocks = <&aoss_qmp>;
		clock-names = "apb_pclk";

		out-ports {
			port {
				tpdm_actpm_out_tpda_apss: endpoint {
					remote-endpoint =
					<&tpda_apss_in_tpdm_actpm>;
				};
			};
		};
	};

	tpdm_apss: tpdm@12861000 {
		compatible = "arm,primecell";
		arm,primecell-periphid = <0x000bb968>;
		reg = <0x12861000 0x1000>;
		reg-names = "tpdm-base";

		coresight-name = "coresight-tpdm-apss";
		atid = <66>;
		clocks = <&aoss_qmp>;
		clock-names = "apb_pclk";

		out-ports {
			port {
				tpdm_apss_out_tpda_apss: endpoint {
					remote-endpoint =
					<&tpda_apss_in_tpdm_apss>;
				};
			};
		};
	};

	tpdm_dcc: tpdm@10003000 {
		compatible = "arm,primecell";
		arm,primecell-periphid = <0x000bb968>;
		reg = <0x10003000 0x1000>;
		reg-names = "tpdm-base";

		coresight-name = "coresight-tpdm-dcc";
		atid = <65>;
		clocks = <&aoss_qmp>;
		clock-names = "apb_pclk";

		qcom,hw-enable-check;
		out-ports {
			port {
				tpdm_dcc_out_tpda_qdss: endpoint {
					remote-endpoint =
					<&tpda_qdss_in_tpdm_dcc>;
				};
			};
		};
	};

	tpdm_dlct0: tpdm@10c28000 {
		compatible = "arm,primecell";
		arm,primecell-periphid = <0x000bb968>;
		reg = <0x10c28000 0x1000>;
		reg-names = "tpdm-base";

		coresight-name = "coresight-tpdm-dlct0";

		clocks = <&aoss_qmp>;
		clock-names = "apb_pclk";
		atid = <78>;

		out-ports {
			port {
				tpdm_dl_ct0_out_tpda_dl_center: endpoint {
					remote-endpoint =
					<&tpda_dl_center_in_tpdm_dl_ct0>;
				};
			};
		};
	};

	tpdm_dlct1: tpdm@10c29000 {
		compatible = "arm,primecell";
		arm,primecell-periphid = <0x000bb968>;
		reg = <0x10c29000 0x1000>;
		reg-names = "tpdm-base";

		coresight-name = "coresight-tpdm-dlct1";
		atid = <78>;
		clocks = <&aoss_qmp>;
		clock-names = "apb_pclk";

		status = "disabled";
		qcom,cmb-msr-skip;
		out-ports {
			port {
				tpdm_dl_ct1_out_tpda_dl_center: endpoint {
					remote-endpoint =
					<&tpda_dl_center_in_tpdm_dl_ct1>;
				};
			};
		};
	};

	tpdm_dlmm: tpdm@10c08000 {
		compatible = "arm,primecell";
		arm,primecell-periphid = <0x000bb968>;
		reg = <0x10c08000 0x1000>;
		reg-names = "tpdm-base";

		coresight-name = "coresight-tpdm-dlmm";

		clocks = <&aoss_qmp>;
		clock-names = "apb_pclk";
		atid = <81>;

		out-ports {
			port {
				tpdm_dlmm_out_tpda_dlmm: endpoint {
					remote-endpoint =
					<&tpda_dlmm_in_tpdm_dlmm>;
				};
			};
		};
	};

	tpdm_dl_north: tpdm@10ac0000 {
		compatible = "arm,primecell";
		arm,primecell-periphid = <0x000bb968>;
		reg = <0x10ac0000 0x1000>;
		reg-names = "tpdm-base";

		coresight-name = "coresight-tpdm-dl-north";
		atid = <97>;
		clocks = <&aoss_qmp>;
		clock-names = "apb_pclk";

		out-ports {
			port {
				tpdm_dl_north_out_tpda_dl_north: endpoint {
					remote-endpoint =
					<&tpda_dl_north_in_tpdm_dl_north>;
				};
			};
		};
	};

	tpdm_spdm: tpdm@1000f000 {
		compatible = "arm,primecell";
		arm,primecell-periphid = <0x000bb968>;
		reg = <0x1000f000 0x1000>;
		reg-names = "tpdm-base";

		coresight-name = "coresight-tpdm-spdm";
		atid = <65>;
		clocks = <&aoss_qmp>;
		clock-names = "apb_pclk";

		out-ports {
			port {
				tpdm_spdm_out_tpda_qdss: endpoint {
					remote-endpoint =
					<&tpda_qdss_in_tpdm_spdm>;
				};
			};
		};
	};

	tpda_ddr_llcc: tpda@10d0c000 {
		compatible = "arm,primecell";
		arm,primecell-periphid = <0x000bb969>;

		reg = <0x10d0c000 0x1000>;
		reg-names = "tpda-base";

		coresight-name = "coresight-tpda-ddr-llcc";

		clocks = <&aoss_qmp>;
		clock-names = "apb_pclk";

		qcom,tpda-atid = <99>;

		qcom,cmb-elem-size = <0 32>,
					<1 32>,
					<2 32>,
					<3 32>;

		in-ports {

			#address-cells = <1>;
			#size-cells = <0>;

			port@0 {
				reg = <0>;
				tpda_ddr_llcc_in_tpdm_ddr_llcc_0: endpoint {
					remote-endpoint =
					<&tpdm_ddr_llcc_0_out_tpda_ddr_llcc>;
				};
			};

			port@1 {
				reg = <1>;
				tpda_ddr_llcc_in_tpdm_ddr_llcc_1: endpoint {
					remote-endpoint =
					<&tpdm_ddr_llcc_1_out_tpda_ddr_llcc>;
				};
			};

			port@2 {
				reg = <2>;
				tpda_ddr_llcc_in_tpdm_ddr_llcc_2: endpoint {
					remote-endpoint =
					<&tpdm_ddr_llcc_2_out_tpda_ddr_llcc>;
				};
			};

			port@3 {
				reg = <3>;
				tpda_ddr_llcc_in_tpdm_ddr_llcc_3: endpoint {
					remote-endpoint =
					<&tpdm_ddr_llcc_3_out_tpda_ddr_llcc>;
				};
			};
		};

		out-ports {

			port {
				tpda_ddr_llcc_out_funnel_ddr_dl_1: endpoint {
					remote-endpoint =
					<&funnel_ddr_dl_1_in_tpda_ddr_llcc>;
				};
			};

		};
	};

	tpda_dl_south: tpda@109c1000 {
		compatible = "arm,primecell";
		arm,primecell-periphid = <0x000bb969>;

		reg = <0x109c1000 0x1000>;
		reg-names = "tpda-base";

		coresight-name = "coresight-tpda-dl_south";

		clocks = <&aoss_qmp>;
		clock-names = "apb_pclk";

		qcom,tpda-atid = <75>;

		qcom,dsb-elem-size = <2 32>;

		in-ports {

			#address-cells = <1>;
			#size-cells = <0>;

			port@2 {
				reg = <2>;
				tpda_dl_south_in_tpdm_dl_south: endpoint {
					remote-endpoint =
					<&tpdm_dl_south_out_tpda_dl_south>;
				};
			};

		};

		out-ports {

			port {
				tpda_dl_south_out_funnel_dl_south: endpoint {
					remote-endpoint =
					<&funnel_dl_south_in_tpda_dl_south>;
				};
			};

		};
	};

	tpda_spss: tpda@10882000 {
		compatible = "arm,primecell";
		arm,primecell-periphid = <0x000bb969>;

		reg = <0x10882000 0x1000>;
		reg-names = "tpda-base";

		coresight-name = "coresight-tpda-spss";

		clocks = <&aoss_qmp>;
		clock-names = "apb_pclk";

		qcom,tpda-atid = <70>;

		qcom,dsb-elem-size = <0 32>;
		qcom,cmb-elem-size = <0 32>;

		status = "disabled";

		in-ports {

			#address-cells = <1>;
			#size-cells = <0>;

			port@0 {
				reg = <0>;
				tpda_spss_in_tpdm_spss: endpoint {
					remote-endpoint =
					<&tpdm_spss_out_tpda_spss>;
				};
			};

		};

		out-ports {

			port {
				tpda_spss_out_funnel_spss: endpoint {
					remote-endpoint =
					<&funnel_spss_in_tpda_spss>;
				};
			};

		};
	};

	tpda_tmess: tpda@10cc7000 {
		compatible = "arm,primecell";
		arm,primecell-periphid = <0x000bb969>;

		reg = <0x10cc7000 0x1000>;
		reg-names = "tpda-base";

		coresight-name = "coresight-tpda-tmess";

		clocks = <&aoss_qmp>;
		clock-names = "apb_pclk";

		qcom,tpda-atid = <85>;

		status = "disabled";
		qcom,dsb-elem-size = <1 32>;
		qcom,cmb-elem-size = <0 32>,
					<1 32>,
					<2 64>;

		in-ports {

			#address-cells = <1>;
			#size-cells = <0>;

			port@0 {
				reg = <0>;
				tpda_tmess_in_tpdm_tmess_prng: endpoint {
					remote-endpoint =
					<&tpdm_tmess_prng_out_tpda_tmess>;
				};
			};

			port@1 {
				reg = <1>;
				tpda_tmess_in_tpdm_tmess1: endpoint {
					remote-endpoint =
					<&tpdm_tmess1_out_tpda_tmess>;
				};
			};

			port@2 {
				reg = <2>;
				tpda_tmess_in_tpdm_tmess0: endpoint {
					remote-endpoint =
					<&tpdm_tmess0_out_tpda_tmess>;
				};
			};
		};

		out-ports {

			port {
				tpda_tmess_out_funnel_tmess: endpoint {
					remote-endpoint =
					<&funnel_tmess_in_tpda_tmess>;
				};
			};
		};
	};

	tpda_apss: tpda@12863000 {
		compatible = "arm,primecell";
		arm,primecell-periphid = <0x000bb969>;

		reg = <0x12863000 0x1000>;
		reg-names = "tpda-base";

		coresight-name = "coresight-tpda-apss";

		clocks = <&aoss_qmp>;
		clock-names = "apb_pclk";

		qcom,tpda-atid = <66>;

		qcom,dsb-elem-size = <4 32>;
		qcom,cmb-elem-size = <0 32>,
					<1 32>,
					<3 64>;

		in-ports {

			#address-cells = <1>;
			#size-cells = <0>;

			port@0 {
				reg = <0>;
				tpda_apss_in_tpdm_llm_gold: endpoint {
					remote-endpoint =
					<&tpdm_llm_gold_out_tpda_apss>;
				};
			};

			port@1 {
				reg = <1>;
				tpda_apss_in_tpdm_llm_gold_plus: endpoint {
					remote-endpoint =
					<&tpdm_llm_gold_plus_out_tpda_apss>;
				};
			};

			port@3 {
				reg = <3>;
				tpda_apss_in_tpdm_actpm: endpoint {
					remote-endpoint =
					<&tpdm_actpm_out_tpda_apss>;
				};
			};

			port@4 {
				reg = <4>;
				tpda_apss_in_tpdm_apss: endpoint {
					remote-endpoint =
					<&tpdm_apss_out_tpda_apss>;
				};
			};
		};

		out-ports {

			port {
				tpda_apss_out_funnel_apss: endpoint {
					remote-endpoint =
					<&funnel_apss_in_tpda_apss>;
				};
			};
		};
	};

	tpda_dl_center: tpda@10c2e000 {
		compatible = "arm,primecell";
		arm,primecell-periphid = <0x000bb969>;

		reg = <0x10c2e000 0x1000>;
		reg-names = "tpda-base";

		coresight-name = "coresight-tpda-dl_center";

		clocks = <&aoss_qmp>;
		clock-names = "apb_pclk";

		qcom,tpda-atid = <78>;

		qcom,dsb-elem-size = <4 32>,
					<5 32>,
					<7 32>,
					<15 32>,
					<17 32>,
					<20 32>,
					<21 32>,
					<26 32>;

		qcom,cmb-elem-size = <7 32>,
					<8 64>,
					<13 64>,
					<14 64>,
					<16 32>,
					<19 32>,
					<22 32>,
					<27 64>;

		in-ports {

			#address-cells = <1>;
			#size-cells = <0>;

			port@4 {
				reg = <4>;
				tpda_dl_center_in_funnel_lpass_dl: endpoint {
					remote-endpoint =
					<&funnel_lpass_dl_out_tpda_dl_center>;
				};
			};

			port@5 {
				reg = <5>;
				tpda_dl_center_5_in_funnel_ddr_dl_0: endpoint {
					remote-endpoint =
					<&funnel_ddr_dl_0_out_tpda_dl_center_5>;
				};
			};

			port@6 {
				reg = <6>;
				tpda_dl_center_6_in_funnel_ddr_dl_0: endpoint {
					remote-endpoint =
					<&funnel_ddr_dl_0_out_tpda_dl_center_6>;
				};
			};

			port@7 {
				reg = <7>;
				tpda_dl_center_7_in_funnel_ddr_dl_0: endpoint {
					remote-endpoint =
					<&funnel_ddr_dl_0_out_tpda_dl_center_7>;
				};
			};

			port@8 {
				reg = <8>;
				tpda_dl_center_8_in_funnel_ddr_dl_0: endpoint {
					remote-endpoint =
					<&funnel_ddr_dl_0_out_tpda_dl_center_8>;
				};
			};

			port@d {
				reg = <13>;
				tpda_dl_center_13_in_funnel_dl_west: endpoint {
					remote-endpoint =
					<&funnel_dl_west_out_tpda_dl_center_13>;
				};
			};

			port@e {
				reg = <14>;
				tpda_dl_center_14_in_funnel_dl_west: endpoint {
					remote-endpoint =
					<&funnel_dl_west_out_tpda_dl_center_14>;
				};
			};

			port@f {
				reg = <15>;
				tpda_dl_center_15_in_funnel_turing: endpoint {
					remote-endpoint =
					<&funnel_turing_out_tpda_dl_center_15>;
				};
			};

			port@10 {
				reg = <16>;
				tpda_dl_center_16_in_funnel_turing: endpoint {
					remote-endpoint =
					<&funnel_turing_out_tpda_dl_center_16>;
				};
			};

			port@11 {
				reg = <17>;
				tpda_dl_center_in_funnel_gpu_dl: endpoint {
					remote-endpoint =
					<&funnel_gpu_dl_out_tpda_dl_center>;
				};
			};

			port@13 {
				reg = <19>;
				tpda_dl_center_in_tpdm_prng: endpoint {
					remote-endpoint =
					<&tpdm_prng_out_tpda_dl_center>;
				};
			};

			port@14 {
				reg = <20>;
				tpda_dl_center_in_tpdm_qm: endpoint {
					remote-endpoint =
					<&tpdm_qm_out_tpda_dl_center>;
				};
			};

			port@15 {
				reg = <21>;
				tpda_dl_center_in_tpdm_gcc: endpoint {
					remote-endpoint =
					<&tpdm_gcc_out_tpda_dl_center>;
				};
			};

			port@16 {
				reg = <22>;
				tpda_dl_center_in_tpdm_vsense: endpoint {
					remote-endpoint =
					<&tpdm_vsense_out_tpda_dl_center>;
				};
			};

			port@17 {
				reg = <23>;
				tpda_dl_center_in_tpdm_ipa: endpoint {
					remote-endpoint =
					<&tpdm_ipa_out_tpda_dl_center>;
				};
			};

			port@1a {
				reg = <26>;
				tpda_dl_center_in_tpdm_dl_ct0: endpoint {
					remote-endpoint =
					<&tpdm_dl_ct0_out_tpda_dl_center>;
				};
			};

			port@1b {
				reg = <27>;
				tpda_dl_center_in_tpdm_dl_ct1: endpoint {
					remote-endpoint =
					<&tpdm_dl_ct1_out_tpda_dl_center>;
				};
			};

		};

		out-ports {

			port {
				tpda_dl_center_out_funnel_dl_center: endpoint {
					remote-endpoint =
					<&funnel_dl_center_in_tpda_dl_center>;
				};
			};
		};
	};

	tpda_dlmm: tpda@10c0b000 {
		compatible = "arm,primecell";
		arm,primecell-periphid = <0x000bb969>;

		reg = <0x10c0b000 0x1000>;
		reg-names = "tpda-base";

		coresight-name = "coresight-tpda-dlmm";

		clocks = <&aoss_qmp>;
		clock-names = "apb_pclk";

		qcom,tpda-atid = <81>;

		qcom,dsb-elem-size = <0 32>,
					<1 32>,
					<2 32>,
					<5 32>;

		qcom,cmb-elem-size = <1 32>,
					<2 32>;

		in-ports {

			#address-cells = <1>;
			#size-cells = <0>;

			port@0 {
				reg = <0>;
				tpda_dlmm_in_funnel_video: endpoint {
					remote-endpoint =
					<&funnel_video_out_tpda_dlmm>;
				};
			};

			port@1 {
				reg = <1>;
				tpda_dlmm_in_tpdm_mdss0: endpoint {
					remote-endpoint =
					<&tpdm_mdss0_out_tpda_dlmm>;
				};
			};

			port@2 {
				reg = <2>;
				tpda_dlmm_in_tpdm_mdss1: endpoint {
					remote-endpoint =
					<&tpdm_mdss1_out_tpda_dlmm>;
				};
			};

			port@5 {
				reg = <5>;
				tpda_dlmm_in_tpdm_dlmm: endpoint {
					remote-endpoint =
					<&tpdm_dlmm_out_tpda_dlmm>;
				};
			};
		};

		out-ports {

			port {
				tpda_dlmm_out_funnel_dlmm: endpoint {
					remote-endpoint =
					<&funnel_dlmm_in_tpda_dlmm>;
				};
			};
		};
	};

	tpda_dl_north: tpda@10ac1000 {
		compatible = "arm,primecell";
		arm,primecell-periphid = <0x000bb969>;

		reg = <0x10ac1000 0x1000>;
		reg-names = "tpda-base";

		coresight-name = "coresight-tpda-dl_north";

		clocks = <&aoss_qmp>;
		clock-names = "apb_pclk";
		qcom,tpda-atid = <97>;

		qcom,dsb-elem-size = <2 32>;
		qcom,cmb-elem-size = <1 32>;

		in-ports {

			#address-cells = <1>;
			#size-cells = <0>;

			port@1 {
				reg = <1>;
				tpda_dl_north_in_tpdm_sdcc: endpoint {
					remote-endpoint =
					<&tpdm_sdcc_out_tpda_dl_north>;
				};
			};

			port@2 {
				reg = <2>;
				tpda_dl_north_in_tpdm_dl_north: endpoint {
					remote-endpoint =
					<&tpdm_dl_north_out_tpda_dl_north>;
				};
			};
		};

		out-ports {

			port {
				tpda_dl_north_out_funnel_dl_north: endpoint {
					remote-endpoint =
					<&funnel_dl_north_in_tpda_dl_north>;
				};
			};
		};
	};

	tpda_qdss: tpda@10004000 {
		compatible = "arm,primecell";
		arm,primecell-periphid = <0x000bb969>;

		reg = <0x10004000 0x1000>;
		reg-names = "tpda-base";

		coresight-name = "coresight-tpda-qdss";

		clocks = <&aoss_qmp>;
		clock-names = "apb_pclk";

		qcom,tpda-atid = <65>;

		qcom,cmb-elem-size = <0 32>,
					<1 32>;

		in-ports {

			#address-cells = <1>;
			#size-cells = <0>;

			port@0 {
				reg = <0>;
				tpda_qdss_in_tpdm_dcc: endpoint {
					remote-endpoint =
					<&tpdm_dcc_out_tpda_qdss>;
				};
			};

			port@1 {
				reg = <1>;
				tpda_qdss_in_tpdm_spdm: endpoint {
					remote-endpoint =
					<&tpdm_spdm_out_tpda_qdss>;
				};
			};
		};

		out-ports {

			port {
				tpda_qdss_out_funnel_in0: endpoint {
					remote-endpoint =
					<&funnel_in0_in_tpda_qdss>;
				};
			};
		};
	};

	tpda_aoss: tpda@10b08000 {
		compatible = "arm,primecell";
		arm,primecell-periphid = <0x000bb969>;

		reg = <0x10b08000 0x1000>;
		reg-names = "tpda-base";

		coresight-name = "coresight-tpda-aoss";

		clocks = <&aoss_qmp>;
		clock-names = "apb_pclk";

		qcom,tpda-atid = <71>;

		/*qcom,dsb-elem-size = <2 32>;*/
		qcom,dsb-elem-size = <4 32>;
		qcom,cmb-elem-size = <0 64>,
					<1 64>,
					<2 64>,
					<3 64>;

		in-ports {

			#address-cells = <1>;
			#size-cells = <0>;

			port@0 {
				reg = <0>;
				tpda_aoss_in_tpdm_swao_prio0: endpoint {
					remote-endpoint =
					<&tpdm_swao_prio0_out_tpda_aoss>;
				};
			};

			port@1 {
				reg = <1>;
				tpda_aoss_in_tpdm_swao_prio1: endpoint {
					remote-endpoint =
					<&tpdm_swao_prio1_out_tpda_aoss>;
				};
			};

			port@2 {
				reg = <2>;
				tpda_aoss_in_tpdm_swao_prio2: endpoint {
					remote-endpoint =
					<&tpdm_swao_prio2_out_tpda_aoss>;
				};
			};


			port@3 {
				reg = <3>;
				tpda_aoss_in_tpdm_swao_prio3: endpoint {
					remote-endpoint =
					<&tpdm_swao_prio3_out_tpda_aoss>;
				};
			};

			port@4 {
				reg = <4>;
				tpda_aoss_in_tpdm_swao: endpoint {
					remote-endpoint =
					<&tpdm_swao_out_tpda_aoss>;
				};
			};
		};

		out-ports {

			port {
				tpda_aoss_out_funnel_aoss: endpoint {
					remote-endpoint =
					<&funnel_aoss_in_tpda_aoss>;
				};
			};
		};
	};


	funnel_etm: funnel@12800000 {
		compatible = "arm,primecell";
		arm,primecell-periphid = <0x000bb908>;

		reg = <0x12800000 0x1000>;
		reg-names = "funnel-base";

		coresight-name = "coresight-funnel-etm";

		clocks = <&aoss_qmp>;
		clock-names = "apb_pclk";

		out-ports {
			port {
				funnel_ete_out_funnel_apss: endpoint {
					remote-endpoint =
					<&funnel_apss_in_funnel_ete>;
				};
			};
		};

		in-ports {
			#address-cells = <1>;
			#size-cells = <0>;

			port@0 {
				reg = <0>;
				funnel_ete_in_ete0: endpoint {
					remote-endpoint =
					<&ete0_out_funnel_ete>;
				};
			};

			port@1 {
				reg = <1>;
				funnel_ete_in_ete1: endpoint {
				remote-endpoint =
					<&ete1_out_funnel_ete>;
				};
			};

			port@2 {
				reg = <2>;
				funnel_ete_in_ete2: endpoint {
				remote-endpoint =
					<&ete2_out_funnel_ete>;
				};
			};

			port@3 {
				reg = <3>;
				funnel_ete_in_ete3: endpoint {
				remote-endpoint =
					<&ete3_out_funnel_ete>;
				};
			};

			port@4 {
				reg = <4>;
				funnel_ete_in_ete4: endpoint {
				remote-endpoint =
					<&ete4_out_funnel_ete>;
				};
			};

			port@5 {
				reg = <5>;
				funnel_ete_in_ete5: endpoint {
					remote-endpoint =
					<&ete5_out_funnel_ete>;
				};
			};

		};
	};

	funnel_ddr_ch_0_2_dl: funnel@10d22000 {
		compatible = "arm,primecell";
		arm,primecell-periphid = <0x000bb908>;

		reg = <0x10d22000 0x1000>;
		reg-names = "funnel-base";

		coresight-name = "coresight-funnel-ddr_ch_0_2_dl";

		clocks = <&aoss_qmp>;
		clock-names = "apb_pclk";

		in-ports {

			#address-cells = <1>;
			#size-cells = <0>;

			port@0 {
				reg = <0>;
					funnel_ddr_ch_0_2_dl_in_tpdm_ddr_ch_0_2: endpoint {
					remote-endpoint =
					<&tpdm_ddr_ch_0_2_out_funnel_ddr_ch_0_2_dl>;
				};
			};
		};

		out-ports {

			port {
				funnel_ddr_ch_0_2_dl_out_funnel_ddr_dl_0: endpoint {
					remote-endpoint =
					<&funnel_ddr_dl_0_in_funnel_ddr_ch_0_2_dl>;
				};
			};
		};
	};

	funnel_ddr_ch_1_3_dl: funnel@10d32000 {
		compatible = "arm,primecell";
		arm,primecell-periphid = <0x000bb908>;

		reg = <0x10d32000 0x1000>;
		reg-names = "funnel-base";

		coresight-name = "coresight-funnel-ddr_ch_1_3_dl";

		clocks = <&aoss_qmp>;
		clock-names = "apb_pclk";

		in-ports {

			#address-cells = <1>;
			#size-cells = <0>;

			port@0 {
				reg = <0>;
					funnel_ddr_ch_1_3_dl_in_tpdm_ddr_ch_1_3: endpoint {
					remote-endpoint =
					<&tpdm_ddr_ch_1_3_out_funnel_ddr_ch_1_3_dl>;
				};
			};
		};

		out-ports {

			port {
				funnel_ddr_ch_1_3_dl_out_funnel_ddr_dl_0: endpoint {
					remote-endpoint =
					<&funnel_ddr_dl_0_in_funnel_ddr_ch_1_3_dl>;
				};
			};
		};
	};

	funnel_ddr_dl_0_dup: funnel@10d06000 {
		compatible = "arm,primecell";
		arm,primecell-periphid = <0x000bb908>;

		reg = <0x10d06000 0x1000>,
			<0x10d05000 0x1000>;
		reg-names = "funnel-base-dummy", "funnel-base-real";

		coresight-name = "coresight-funnel-ddr_dl_0_dup";

		qcom,duplicate-funnel;
		clocks = <&aoss_qmp>;
		clock-names = "apb_pclk";

		in-ports {
			#address-cells = <1>;
			#size-cells = <0>;

			port@4 {
				reg = <4>;
					funnel_ddr_dl_0_in_funnel_ddr_dl_1: endpoint {
					remote-endpoint =
					<&funnel_ddr_dl_1_out_funnel_ddr_dl_0>;
				};
			};

		};

		out-ports {
			port {
				funnel_ddr_dl_0_dup_out_funnel_dl_center: endpoint {
					remote-endpoint =
					<&funnel_dl_center_in_funnel_ddr_dl_0_dup>;
				};
			};
		};
	};


	funnel_ddr_dl_0: funnel@10d05000 {
		compatible = "arm,primecell";
		arm,primecell-periphid = <0x000bb908>;

		reg = <0x10d05000 0x1000>;
		reg-names = "funnel-base";

		coresight-name = "coresight-funnel-ddr_dl_0";

		clocks = <&aoss_qmp>;
		clock-names = "apb_pclk";

		in-ports {

			#address-cells = <1>;
			#size-cells = <0>;

			port@0 {
				reg = <0>;
					funnel_ddr_dl_0_in_funnel_ddr_ch_0_2_dl: endpoint {
					remote-endpoint =
					<&funnel_ddr_ch_0_2_dl_out_funnel_ddr_dl_0>;
				};
			};

			port@1 {
				reg = <1>;
					funnel_ddr_dl_0_in_funnel_ddr_ch_1_3_dl: endpoint {
					remote-endpoint =
					<&funnel_ddr_ch_1_3_dl_out_funnel_ddr_dl_0>;
				};
			};

			port@2 {
				reg = <2>;
					funnel_ddr_dl_0_in_tpdm_ddr_dl_0: endpoint {
					remote-endpoint =
					<&tpdm_ddr_dl_0_out_funnel_ddr_dl_0>;
				};
			};

			port@3 {
				reg = <3>;
					funnel_ddr_dl_0_in_tpdm_ddr_dpm: endpoint {
					remote-endpoint =
					<&tpdm_ddr_dpm_out_funnel_ddr_dl_0>;
				};
			};
		};

		out-ports {
			#address-cells = <1>;
			#size-cells = <0>;

			port@0 {
				reg = <0>;
				funnel_ddr_dl_0_out_tpda_dl_center_5: endpoint {
					remote-endpoint =
					<&tpda_dl_center_5_in_funnel_ddr_dl_0>;
					source = <&tpdm_ddr_ch02>;
				};
			};

			port@1 {
				reg = <1>;
				funnel_ddr_dl_0_out_tpda_dl_center_6: endpoint {
					remote-endpoint =
					<&tpda_dl_center_6_in_funnel_ddr_dl_0>;
					source = <&tpdm_ddr_ch13>;
				};
			};

			port@2 {
				reg = <2>;
				funnel_ddr_dl_0_out_tpda_dl_center_7: endpoint {
					remote-endpoint =
					<&tpda_dl_center_7_in_funnel_ddr_dl_0>;
					source = <&tpdm_ddr_dl_0>;
				};
			};

			port@3 {
				reg = <3>;
				funnel_ddr_dl_0_out_tpda_dl_center_8: endpoint {
					remote-endpoint =
					<&tpda_dl_center_8_in_funnel_ddr_dl_0>;
					source = <&tpdm_ddr_dpm>;
				};
			};
		};
	};

	funnel_ddr_dl_1: funnel@10d0d000 {
		compatible = "arm,primecell";
		arm,primecell-periphid = <0x000bb908>;

		reg = <0x10d0d000 0x1000>;
		reg-names = "funnel-base";

		coresight-name = "coresight-funnel-ddr_dl_1";

		clocks = <&aoss_qmp>;
		clock-names = "apb_pclk";

		in-ports {

			#address-cells = <1>;
			#size-cells = <0>;

			port@0 {
				reg = <0>;
					funnel_ddr_dl_1_in_tpda_ddr_llcc: endpoint {
					remote-endpoint =
					<&tpda_ddr_llcc_out_funnel_ddr_dl_1>;
				};
			};
		};

		out-ports {

			port {
				funnel_ddr_dl_1_out_funnel_ddr_dl_0: endpoint {
					remote-endpoint =
					<&funnel_ddr_dl_0_in_funnel_ddr_dl_1>;
				};
			};
		};
	};

	funnel_turing_dup: funnel@10986000 {
		compatible = "arm,primecell";
		arm,primecell-periphid = <0x000bb908>;

		reg = <0x10986000 0x1000>,
			<0x10985000 0x1000>;
		reg-names = "funnel-base-dummy", "funnel-base-real";

		coresight-name = "coresight-funnel-turing_dup";

		qcom,duplicate-funnel;
		clocks = <&aoss_qmp>;
		clock-names = "apb_pclk";

		in-ports {
			#address-cells = <1>;
			#size-cells = <0>;
			port@3 {
				reg = <3>;
				funnel_turing_dup_in_turing_etm: endpoint {
					remote-endpoint =
					<&turing_etm_out_funnel_turing_dup>;
				};
			};
		};

		out-ports {
			port {
				funnel_turing_dup_out_funnel_turing: endpoint {
					remote-endpoint =
					<&funnel_turing_in_funnel_turing_dup>;
				};
			};
		};
	};

	funnel_turing: funnel@10985000 {
		compatible = "arm,primecell";
		arm,primecell-periphid = <0x000bb908>;

		reg = <0x10985000 0x1000>;
		reg-names = "funnel-base";

		coresight-name = "coresight-funnel-turing";

		clocks = <&aoss_qmp>;
		clock-names = "apb_pclk";

		in-ports {

			#address-cells = <1>;
			#size-cells = <0>;

			port@0 {
				reg = <0>;
					funnel_turing_in_tpdm_turing: endpoint {
					remote-endpoint =
					<&tpdm_turing_out_funnel_turing>;
				};
			};

			port@1 {
				reg = <1>;
					funnel_turing_in_tpdm_turing_llm: endpoint {
					remote-endpoint =
					<&tpdm_turing_llm_out_funnel_turing>;
				};
			};

			port@4 {
				reg = <4>;
					funnel_turing_in_funnel_turing_dup: endpoint {
					remote-endpoint =
					<&funnel_turing_dup_out_funnel_turing>;
				};
			};
		};

		out-ports {
			#address-cells = <1>;
			#size-cells = <0>;

			port@0 {
				reg = <0>;
				funnel_turing_out_tpda_dl_center_15: endpoint {
					remote-endpoint =
					<&tpda_dl_center_15_in_funnel_turing>;
					source = <&tpdm_turing>;
				};
			};

			port@1 {
				reg = <1>;
				funnel_turing_out_tpda_dl_center_16: endpoint {
					remote-endpoint =
					<&tpda_dl_center_16_in_funnel_turing>;
					source = <&tpdm_turing_llm>;
				};
			};

			port@2 {
				reg = <2>;
				funnel_turing_out_funnel_dl_center: endpoint {
					remote-endpoint =
					<&funnel_dl_center_in_funnel_turing>;
				};
			};
		};
	};

	funnel_gpu_dl: funnel@10902000 {
		compatible = "arm,primecell";
		arm,primecell-periphid = <0x000bb908>;

		reg = <0x10902000 0x1000>;
		reg-names = "funnel-base";

		coresight-name = "coresight-funnel-gpu_dl";
		clocks = <&aoss_qmp>;
		clock-names = "apb_pclk";

		in-ports {

			#address-cells = <1>;
			#size-cells = <0>;

			port@0 {
				reg = <0>;
				funnel_gpu_dl_in_tpdm_gpu: endpoint {
					remote-endpoint =
					<&tpdm_gpu_out_funnel_gpu_dl>;
				};
			};
		};

		out-ports {

			port {
				funnel_gpu_dl_out_tpda_dl_center: endpoint {
					remote-endpoint =
					<&tpda_dl_center_in_funnel_gpu_dl>;
				};
			};
		};
	};

	funnel_dl_west: funnel@10c3a000 {
		compatible = "arm,primecell";
		arm,primecell-periphid = <0x000bb908>;

		reg = <0x10c3a000 0x1000>;
		reg-names = "funnel-base";

		coresight-name = "coresight-funnel-dl_west";

		clocks = <&aoss_qmp>;
		clock-names = "apb_pclk";

		in-ports {

			#address-cells = <1>;
			#size-cells = <0>;

			port@0 {
				reg = <0>;
				funnel_dl_west_in_tpdm_rdpm: endpoint {
					remote-endpoint =
					<&tpdm_rdpm_out_funnel_dl_west>;
				};
			};

			port@1 {
				reg = <1>;
				funnel_dl_west_in_tpdm_rdpm_mx: endpoint {
					remote-endpoint =
					<&tpdm_rdpm_mx_out_funnel_dl_west>;
				};
			};
		};

		out-ports {
			#address-cells = <1>;
			#size-cells = <0>;

			port@0 {
				reg = <0>;
				funnel_dl_west_out_tpda_dl_center_13: endpoint {
					remote-endpoint =
					<&tpda_dl_center_13_in_funnel_dl_west>;
					source = <&tpdm_rdpm>;
				};
			};

			port@1 {
				reg = <1>;
				funnel_dl_west_out_tpda_dl_center_14: endpoint {
					remote-endpoint =
					<&tpda_dl_center_14_in_funnel_dl_west>;
					source = <&tpdm_rdpm_mx>;
				};
			};
		};
	};

	funnel_lpass_lpi: funnel@10b44000 {
		compatible = "arm,coresight-static-funnel";
		coresight-name = "coresight-funnel-lpass_lpi";

		in-ports {

			#address-cells = <1>;
			#size-cells = <0>;

			port@0 {
				reg = <0>;
				funnel_lpass_lpi_in_audio_etm: endpoint {
					remote-endpoint =
					<&audio_etm_out_funnel_lpass_lpi>;
				};
			};

			port@4 {
				reg = <4>;
				funnel_lpass_lpi_in_lpass_stm: endpoint {
					remote-endpoint =
					<&lpass_stm_out_funnel_lpass_lpi>;
				};
			};

			port@5 {
				reg = <5>;
				funnel_lpass_lpi_in_tpdm_lpass_lpi: endpoint {
					remote-endpoint =
					<&tpdm_lpass_lpi_out_funnel_lpass_lpi>;
				};
			};
		};

		out-ports {

			port {
				funnel_lpass_lpi_out_funnel_aoss: endpoint {
					remote-endpoint =
					<&funnel_aoss_in_funnel_lpass_lpi>;
				};
			};
		};
	};

	funnel_lpass_dl: funnel@10846000 {
		compatible = "arm,primecell";
		arm,primecell-periphid = <0x000bb908>;

		reg = <0x10846000 0x1000>;
		reg-names = "funnel-base";

		coresight-name = "coresight-funnel-lpass_dl";

		clocks = <&aoss_qmp>;
		clock-names = "apb_pclk";

		in-ports {

			#address-cells = <1>;
			#size-cells = <0>;

			port@0 {
				reg = <0>;
				funnel_lpass_dl_in_tpdm_lpass: endpoint {
					remote-endpoint =
					<&tpdm_lpass_out_funnel_lpass_dl>;
				};
			};
		};

		out-ports {

			port {
				funnel_lpass_dl_out_tpda_dl_center: endpoint {
					remote-endpoint =
					<&tpda_dl_center_in_funnel_lpass_dl>;
				};
			};
		};
	};

	funnel_dl_south: funnel@109c2000 {
		compatible = "arm,primecell";
		arm,primecell-periphid = <0x000bb908>;

		reg = <0x109c2000 0x1000>;
		reg-names = "funnel-base";

		coresight-name = "coresight-funnel-dl_south";

		clocks = <&aoss_qmp>;
		clock-names = "apb_pclk";

		in-ports {

			#address-cells = <1>;
			#size-cells = <0>;

			port@0 {
				reg = <0>;
				funnel_dl_south_in_tpda_dl_south: endpoint {
					remote-endpoint =
					<&tpda_dl_south_out_funnel_dl_south>;
				};
			};
		};

		out-ports {

			port {
				funnel_dl_south_out_funnel_dlmm: endpoint {
					remote-endpoint =
					<&funnel_dlmm_in_funnel_dl_south>;
				};
			};
		};
	};

	funnel_video: funnel@10832000 {
		compatible = "arm,primecell";
		arm,primecell-periphid = <0x000bb908>;

		reg = <0x10832000 0x1000>;
		reg-names = "funnel-base";

		coresight-name = "coresight-funnel-video";
		clocks = <&aoss_qmp>;
		clock-names = "apb_pclk";

		in-ports {

			#address-cells = <1>;
			#size-cells = <0>;

			port@0 {
				reg = <0>;
				funnel_video_in_tpdm_video: endpoint {
					remote-endpoint =
					<&tpdm_video_out_funnel_video>;
				};
			};
		};

		out-ports {

			port {
				funnel_video_out_tpda_dlmm: endpoint {
					remote-endpoint =
					<&tpda_dlmm_in_funnel_video>;
				};
			};
		};
	};

	funnel_spss: funnel@10883000 {
		compatible = "arm,primecell";
		arm,primecell-periphid = <0x000bb908>;

		reg = <0x10883000 0x1000>;
		reg-names = "funnel-base";

		coresight-name = "coresight-funnel-spss";
		clocks = <&aoss_qmp>;
		clock-names = "apb_pclk";

		status = "disabled";
		in-ports {

			#address-cells = <1>;
			#size-cells = <0>;

			port@0 {
				reg = <0>;
				funnel_spss_in_tpda_spss: endpoint {
					remote-endpoint =
					<&tpda_spss_out_funnel_spss>;
				};
			};
		};

		out-ports {

			port {
				funnel_spss_out_funnel_dl_north: endpoint {
					remote-endpoint =
					<&funnel_dl_north_in_funnel_spss>;
				};
			};
		};
	};

	funnel_tmess: funnel@10cc8000 {
		compatible = "arm,primecell";
		arm,primecell-periphid = <0x000bb908>;

		reg = <0x10cc8000 0x1000>;
		reg-names = "funnel-base";

		coresight-name = "coresight-funnel-tmess";

		clocks = <&aoss_qmp>;
		clock-names = "apb_pclk";

		status = "disabled";
		in-ports {

			#address-cells = <1>;
			#size-cells = <0>;

			port@0 {
				reg = <0>;
				funnel_tmess_in_tpda_tmess: endpoint {
					remote-endpoint =
					<&tpda_tmess_out_funnel_tmess>;
				};
			};
		};

		out-ports {

			port {
				funnel_tmess_out_funnel_in1: endpoint {
					remote-endpoint =
					<&funnel_in1_in_funnel_tmess>;
				};
			};
		};
	};

	funnel_apss: funnel@12810000 {
		compatible = "arm,primecell";
		arm,primecell-periphid = <0x000bb908>;

		reg = <0x12810000 0x1000>;
		reg-names = "funnel-base";

		coresight-name = "coresight-funnel-apss";

		clocks = <&aoss_qmp>;
		clock-names = "apb_pclk";

		in-ports {

			#address-cells = <1>;
			#size-cells = <0>;

			port@0 {
				reg = <0>;
				funnel_apss_in_funnel_ete: endpoint {
					remote-endpoint =
					<&funnel_ete_out_funnel_apss>;
				};
			};

			port@3 {
				reg = <3>;
				funnel_apss_in_tpda_apss: endpoint {
				remote-endpoint =
					<&tpda_apss_out_funnel_apss>;
				};
			};
		};

		out-ports {

			port {
				funnel_apss_out_funnel_in1: endpoint {
					remote-endpoint =
					<&funnel_in1_in_funnel_apss>;
				};
			};
		};
	};

	funnel_dl_center: funnel@10c2f000 {
		compatible = "arm,primecell";
		arm,primecell-periphid = <0x000bb908>;

		reg = <0x10c2f000 0x1000>;
		reg-names = "funnel-base";

		coresight-name = "coresight-funnel-dl_center";

		clocks = <&aoss_qmp>;
		clock-names = "apb_pclk";

		in-ports {

			#address-cells = <1>;
			#size-cells = <0>;

			port@0 {
				reg = <0>;
				funnel_dl_center_in_tpda_dl_center: endpoint {
					remote-endpoint =
					<&tpda_dl_center_out_funnel_dl_center>;
				};
			};

			port@4 {
				reg = <4>;
				funnel_dl_center_in_funnel_ddr_dl_0_dup: endpoint {
					remote-endpoint =
					<&funnel_ddr_dl_0_dup_out_funnel_dl_center>;
				};
			};

			port@6 {
				reg = <6>;
				funnel_dl_center_in_funnel_turing: endpoint {
					remote-endpoint =
					<&funnel_turing_out_funnel_dl_center>;
				};
			};
		};

		out-ports {

			port {
				funnel_dl_center_out_funnel_in1: endpoint {
					remote-endpoint =
					<&funnel_in1_in_funnel_dl_center>;
				};
			};
		};
	};

	funnel_dlmm: funnel@10c0c000 {
		compatible = "arm,primecell";
		arm,primecell-periphid = <0x000bb908>;

		reg = <0x10c0c000 0x1000>;
		reg-names = "funnel-base";

		coresight-name = "coresight-funnel-dlmm";

		clocks = <&aoss_qmp>;
		clock-names = "apb_pclk";

		in-ports {

			#address-cells = <1>;
			#size-cells = <0>;

			port@0 {
				reg = <0>;
				funnel_dlmm_in_tpda_dlmm: endpoint {
					remote-endpoint =
					<&tpda_dlmm_out_funnel_dlmm>;
				};
			};

			port@4 {
				reg = <4>;
				funnel_dlmm_in_funnel_dl_south: endpoint {
					remote-endpoint =
					<&funnel_dl_south_out_funnel_dlmm>;
				};
			};
		};

		out-ports {

			port {
				funnel_dlmm_out_funnel_in1: endpoint {
					remote-endpoint =
					<&funnel_in1_in_funnel_dlmm>;
				};
			};
		};
	};

	funnel_dl_north: funnel@10ac2000 {
		compatible = "arm,primecell";
		arm,primecell-periphid = <0x000bb908>;

		reg = <0x10ac2000 0x1000>;
		reg-names = "funnel-base";

		coresight-name = "coresight-funnel-dl_north";

		clocks = <&aoss_qmp>;
		clock-names = "apb_pclk";

		in-ports {

			#address-cells = <1>;
			#size-cells = <0>;

			port@0 {
				reg = <0>;
				funnel_dl_north_in_tpda_dl_north: endpoint {
					remote-endpoint =
					<&tpda_dl_north_out_funnel_dl_north>;
				};
			};

			port@3 {
				reg = <3>;
				funnel_dl_north_in_funnel_spss: endpoint {
					remote-endpoint =
					<&funnel_spss_out_funnel_dl_north>;
				};
			};

		};

		out-ports {

			port {
				funnel_dl_north_out_funnel_in1: endpoint {
					remote-endpoint =
					<&funnel_in1_in_funnel_dl_north>;
				};
			};
		};
	};

	funnel_in0: funnel@10041000 {
		compatible = "arm,primecell";
		arm,primecell-periphid = <0x000bb908>;

		reg = <0x10041000 0x1000>;
		reg-names = "funnel-base";

		coresight-name = "coresight-funnel-in0";

		clocks = <&aoss_qmp>;
		clock-names = "apb_pclk";

		in-ports {

			#address-cells = <1>;
			#size-cells = <0>;

			port@0 {
				reg = <0>;
				funnel_in0_in_snoc: endpoint {
					remote-endpoint =
					<&snoc_out_funnel_in0>;
				};
			};

			port@6 {
				reg = <6>;
				funnel_in0_in_tpda_qdss: endpoint {
					remote-endpoint =
					<&tpda_qdss_out_funnel_in0>;
				};
			};

			port@7 {
				reg = <7>;
				funnel_in0_in_stm: endpoint {
					remote-endpoint =
					<&stm_out_funnel_in0>;
				};
			};
		};

		out-ports {

			port {
				funnel_in0_out_funnel_merge: endpoint {
					remote-endpoint =
					<&funnel_merge_in_funnel_in0>;
				};
			};
		};
	};

	funnel_in1: funnel@10042000 {
		compatible = "arm,primecell";
		arm,primecell-periphid = <0x000bb908>;

		reg = <0x10042000 0x1000>;
		reg-names = "funnel-base";

		coresight-name = "coresight-funnel-in1";

		clocks = <&aoss_qmp>;
		clock-names = "apb_pclk";

		in-ports {

			#address-cells = <1>;
			#size-cells = <0>;

			port@0 {
				reg = <0>;
				funnel_in1_in_funnel_tmess: endpoint {
					remote-endpoint =
					<&funnel_tmess_out_funnel_in1>;
				};
			};

			port@1 {
				reg = <1>;
				funnel_in1_in_funnel_dl_north: endpoint {
					remote-endpoint =
					<&funnel_dl_north_out_funnel_in1>;
				};
			};

			port@2 {
				reg = <2>;
				funnel_in1_in_funnel_dlmm: endpoint {
					remote-endpoint =
					<&funnel_dlmm_out_funnel_in1>;
				};
			};

			port@4 {
				reg = <4>;
				funnel_in1_in_funnel_apss: endpoint {
					remote-endpoint =
					<&funnel_apss_out_funnel_in1>;
				};
			};

			port@6 {
				reg = <6>;
				funnel_in1_in_funnel_dl_center: endpoint {
					remote-endpoint =
					<&funnel_dl_center_out_funnel_in1>;
				};
			};
		};

		out-ports {

			port {
				funnel_in1_out_funnel_merge: endpoint {
					remote-endpoint =
					<&funnel_merge_in_funnel_in1>;
				};
			};
		};
	};

	funnel_merge: funnel@10045000 {
		compatible = "arm,primecell";
		arm,primecell-periphid = <0x000bb908>;

		reg = <0x10045000 0x1000>;
		reg-names = "funnel-base";

		coresight-name = "coresight-funnel-merge";

		clocks = <&aoss_qmp>;
		clock-names = "apb_pclk";

		in-ports {

			#address-cells = <1>;
			#size-cells = <0>;

			port@0 {
				reg = <0>;
				funnel_merge_in_funnel_in0: endpoint {
					remote-endpoint =
					<&funnel_in0_out_funnel_merge>;
				};
			};

			port@1 {
				reg = <1>;
				funnel_merge_in_funnel_in1: endpoint {
					remote-endpoint =
					<&funnel_in1_out_funnel_merge>;
				};
			};
		};

		out-ports {

			port {
				funnel_merge_out_funnel_aoss: endpoint {
					remote-endpoint =
					<&funnel_aoss_in_funnel_merge>;
				};
			};
		};
	};

	funnel_aoss: funnel@10b04000 {
		compatible = "arm,primecell";
		arm,primecell-periphid = <0x000bb908>;

		reg = <0x10b04000 0x1000>;
		reg-names = "funnel-base";

		coresight-name = "coresight-funnel-aoss";

		clocks = <&aoss_qmp>;
		clock-names = "apb_pclk";

		in-ports {

			#address-cells = <1>;
			#size-cells = <0>;

			port@5 {
				reg = <5>;
				funnel_aoss_in_funnel_lpass_lpi: endpoint {
					remote-endpoint =
					<&funnel_lpass_lpi_out_funnel_aoss>;
				};
			};

			port@7 {
				reg = <7>;
				funnel_aoss_in_funnel_merge: endpoint {
					remote-endpoint =
					<&funnel_merge_out_funnel_aoss>;
				};
			};

			port@6 {
				reg = <6>;
				funnel_aoss_in_tpda_aoss: endpoint {
					remote-endpoint =
					<&tpda_aoss_out_funnel_aoss>;
				};
			};
		};

		out-ports {

			port {
				funnel_aoss_out_tmc_etf: endpoint {
					remote-endpoint =
					<&tmc_etf_in_funnel_aoss>;
				};
			};
		};
	};


	apss_cti0: cti@128e0000 {
		compatible = "arm,coresight-cti", "arm,primecell";
		reg = <0x128e0000 0x1000>;

		arm,primecell-periphid = <0x000bb922>;
		coresight-name = "coresight-cti-apss_cti0";

		clocks = <&aoss_qmp>;
		clock-names = "apb_pclk";
	};

	apss_cti1: cti@128f0000 {
		compatible = "arm,coresight-cti", "arm,primecell";
		reg = <0x128f0000 0x1000>;

		arm,primecell-periphid = <0x000bb922>;
		coresight-name = "coresight-cti-apss_cti1";

		clocks = <&aoss_qmp>;
		clock-names = "apb_pclk";
	};

	apss_cti2: cti@12900000 {
		compatible = "arm,coresight-cti", "arm,primecell";
		reg = <0x12900000 0x1000>;

		arm,primecell-periphid = <0x000bb922>;
		coresight-name = "coresight-cti-apss_cti2";

		clocks = <&aoss_qmp>;
		clock-names = "apb_pclk";
	};

	cortex_m3: cti@10b13000 {
		compatible = "arm,coresight-cti", "arm,primecell";
		reg = <0x10b13000 0x1000>;

		arm,primecell-periphid = <0x000bb922>;
		coresight-name = "coresight-cti-cortex_m3";

		clocks = <&aoss_qmp>;
		clock-names = "apb_pclk";
	};

	cti0: cti@10c2a000 {
		compatible = "arm,coresight-cti", "arm,primecell";
		reg = <0x10c2a000 0x1000>;

		arm,primecell-periphid = <0x000bb922>;
		coresight-name = "coresight-cti-cti0";

		clocks = <&aoss_qmp>;
		clock-names = "apb_pclk";
	};

	cti1: cti@10c2b000 {
		compatible = "arm,coresight-cti", "arm,primecell";
		reg = <0x10c2b000 0x1000>;

		arm,primecell-periphid = <0x000bb922>;
		coresight-name = "coresight-cti-cti1";

		clocks = <&aoss_qmp>;
		clock-names = "apb_pclk";
	};

	ddr_ch02_dl_cti_0: cti@10d21000 {
		compatible = "arm,coresight-cti", "arm,primecell";
		reg = <0x10d21000 0x1000>;

		arm,primecell-periphid = <0x000bb922>;
		coresight-name = "coresight-cti-ddr_ch02_dl_cti_0";

		clocks = <&aoss_qmp>;
		clock-names = "apb_pclk";
	};

	ddr_ch13_dl_cti_0: cti@10d31000 {
		compatible = "arm,coresight-cti", "arm,primecell";
		reg = <0x10d31000 0x1000>;

		arm,primecell-periphid = <0x000bb922>;
		coresight-name = "coresight-cti-ddr_ch13_dl_cti_0";

		clocks = <&aoss_qmp>;
		clock-names = "apb_pclk";
	};

	ddr_dl_0_cti_0: cti@10d02000 {
		compatible = "arm,coresight-cti", "arm,primecell";
		reg = <0x10d02000 0x1000>;

		arm,primecell-periphid = <0x000bb922>;
		coresight-name = "coresight-cti-ddr_dl_0_cti_0";

		clocks = <&aoss_qmp>;
		clock-names = "apb_pclk";
	};

	ddr_dl_1_cti_0: cti@10d08000 {
		compatible = "arm,coresight-cti", "arm,primecell";
		reg = <0x10d08000 0x1000>;

		arm,primecell-periphid = <0x000bb922>;
		coresight-name = "coresight-cti-ddr_dl_1_cti_0";

		clocks = <&aoss_qmp>;
		clock-names = "apb_pclk";
	};

	ddr_dl_1_cti_1: cti@10d09000 {
		compatible = "arm,coresight-cti", "arm,primecell";
		reg = <0x10d09000 0x1000>;

		arm,primecell-periphid = <0x000bb922>;
		coresight-name = "coresight-cti-ddr_dl_1_cti_1";

		clocks = <&aoss_qmp>;
		clock-names = "apb_pclk";
	};

	ddr_dl_1_cti_2: cti@10d0a000 {
		compatible = "arm,coresight-cti", "arm,primecell";
		reg = <0x10d0a000 0x1000>;

		arm,primecell-periphid = <0x000bb922>;
		coresight-name = "coresight-cti-ddr_dl_1_cti_2";

		clocks = <&aoss_qmp>;
		clock-names = "apb_pclk";
	};

	ddrss_shrm2: cti@10d11000 {
		compatible = "arm,coresight-cti", "arm,primecell";
		reg = <0x10d11000 0x1000>;

		arm,primecell-periphid = <0x000bb922>;
		coresight-name = "coresight-cti-ddrss_shrm2";

		status = "disabled";
		clocks = <&aoss_qmp>;
		clock-names = "apb_pclk";
	};

	gpu_cortex_m3: cti@10962000 {
		compatible = "arm,coresight-cti", "arm,primecell";
		reg = <0x10962000 0x1000>;

		arm,primecell-periphid = <0x000bb922>;
		coresight-name = "coresight-cti-gpu_cortex_m3";

		status = "disabled";
		clocks = <&aoss_qmp>;
		clock-names = "apb_pclk";
	};

	gpu_dl_cti: cti@10901000 {
		compatible = "arm,coresight-cti", "arm,primecell";
		reg = <0x10901000 0x1000>;

		arm,primecell-periphid = <0x000bb922>;
		coresight-name = "coresight-cti-gpu_dl";

		qcom,extended_cti;
		clocks = <&aoss_qmp>;
		clock-names = "apb_pclk";
	};

	gpu_isdb_cti: cti@10961000 {
		compatible = "arm,coresight-cti", "arm,primecell";
		reg = <0x10961000 0x1000>;

		arm,primecell-periphid = <0x000bb922>;
		coresight-name = "coresight-cti-gpu_isdb_cti";

		status = "disabled";
		clocks = <&aoss_qmp>;
		clock-names = "apb_pclk";
	};

	iris_dl_cti: cti@10831000 {
		compatible = "arm,coresight-cti", "arm,primecell";
		reg = <0x10831000 0x1000>;

		arm,primecell-periphid = <0x000bb922>;
		coresight-name = "coresight-cti-iris_dl_cti";

		clocks = <&aoss_qmp>;
		clock-names = "apb_pclk";
	};

	lpass_dl_cti: cti@10845000 {
		compatible = "arm,coresight-cti", "arm,primecell";
		reg = <0x10845000 0x1000>;

		arm,primecell-periphid = <0x000bb922>;
		coresight-name = "coresight-cti-lpass_dl_cti";

		clocks = <&aoss_qmp>;
		clock-names = "apb_pclk";
	};

	lpass_lpi_cti: cti@10b41000 {
		compatible = "arm,coresight-cti", "arm,primecell";
		reg = <0x10b41000 0x1000>;

		arm,primecell-periphid = <0x000bb922>;
		coresight-name = "coresight-cti-lpass_lpi_cti";

		status = "disabled";
		clocks = <&aoss_qmp>;
		clock-names = "apb_pclk";
	};

	lpass_q6_cti: cti@10b4b000 {
		compatible = "arm,coresight-cti", "arm,primecell";
		reg = <0x10b4b000 0x1000>;

		arm,primecell-periphid = <0x000bb922>;
		coresight-name = "coresight-cti-lpass_q6_cti";

		status = "disabled";
		clocks = <&aoss_qmp>;
		clock-names = "apb_pclk";
	};

	qc_cti: cti@10010000 {
		compatible = "arm,coresight-cti", "arm,primecell";
		reg = <0x10010000 0x1000>;

		arm,primecell-periphid = <0x000bb922>;
		coresight-name = "coresight-cti-qc_cti";

		qcom,extended_cti;
		clocks = <&aoss_qmp>;
		clock-names = "apb_pclk";

	};

	riscv_cti: cti@1282b000 {
		compatible = "arm,coresight-cti", "arm,primecell";
		reg = <0x1282b000 0x1000>;

		arm,primecell-periphid = <0x000bb922>;
		coresight-name = "coresight-cti-riscv_cti";

		status = "disabled";

		clocks = <&aoss_qmp>;
		clock-names = "apb_pclk";
	};

	sp_sc300: cti@10884000 {
		compatible = "arm,coresight-cti", "arm,primecell";
		reg = <0x10884000 0x1000>;

		arm,primecell-periphid = <0x000bb922>;
		coresight-name = "coresight-cti-sp_sc300";

		clocks = <&aoss_qmp>;
		clock-names = "apb_pclk";
	};

	spss_cti: cti@10881000 {
		compatible = "arm,coresight-cti", "arm,primecell";
		reg = <0x10881000 0x1000>;

		arm,primecell-periphid = <0x000bb922>;
		coresight-name = "coresight-cti-spss_cti";

		status = "disabled";

		clocks = <&aoss_qmp>;
		clock-names = "apb_pclk";
	};

	swao_cti: cti@10b00000 {
		compatible = "arm,coresight-cti", "arm,primecell";
		reg = <0x10b00000 0x1000>;

		arm,primecell-periphid = <0x000bb922>;
		coresight-name = "coresight-cti-swao_cti";

		qcom,extended_cti;
		clocks = <&aoss_qmp>;
		clock-names = "apb_pclk";
	};

	tmess_cpu: cti@10cd1000 {
		compatible = "arm,coresight-cti", "arm,primecell";
		reg = <0x10cd1000 0x1000>;

		arm,primecell-periphid = <0x000bb922>;
		coresight-name = "coresight-cti-tmess_cpu";

		status = "disabled";
		clocks = <&aoss_qmp>;
		clock-names = "apb_pclk";
	};

	tmess_cti_0: cti@10cc2000 {
		compatible = "arm,coresight-cti", "arm,primecell";
		reg = <0x10cc2000 0x1000>;

		arm,primecell-periphid = <0x000bb922>;
		coresight-name = "coresight-cti-tmess_cti_0";

		clocks = <&aoss_qmp>;
		clock-names = "apb_pclk";
	};

	tmess_cti_1: cti@10cc3000 {
		compatible = "arm,coresight-cti", "arm,primecell";
		reg = <0x10cc3000 0x1000>;

		arm,primecell-periphid = <0x000bb922>;
		coresight-name = "coresight-cti-tmess_cti_1";

		clocks = <&aoss_qmp>;
		clock-names = "apb_pclk";
	};

	tmess_cti_2: cti@10cc4000 {
		compatible = "arm,coresight-cti", "arm,primecell";
		reg = <0x10cc4000 0x1000>;

		arm,primecell-periphid = <0x000bb922>;
		coresight-name = "coresight-cti-tmess_cti_2";

		clocks = <&aoss_qmp>;
		clock-names = "apb_pclk";
	};


	tmess_cti_3: cti@10cc5000 {
		compatible = "arm,coresight-cti", "arm,primecell";
		reg = <0x10cc5000 0x1000>;

		arm,primecell-periphid = <0x000bb922>;
		coresight-name = "coresight-cti-tmess_cti_3";

		clocks = <&aoss_qmp>;
		clock-names = "apb_pclk";
	};

	tmess_cti_4: cti@10cc6000 {
		compatible = "arm,coresight-cti", "arm,primecell";
		reg = <0x10cc6000 0x1000>;

		arm,primecell-periphid = <0x000bb922>;
		coresight-name = "coresight-cti-tmess_cti_4";

		clocks = <&aoss_qmp>;
		clock-names = "apb_pclk";
	};

	turing_dl_cti_0: cti@10982000 {
		compatible = "arm,coresight-cti", "arm,primecell";
		reg = <0x10982000 0x1000>;

		arm,primecell-periphid = <0x000bb922>;
		coresight-name = "coresight-cti-turing_dl_cti_0";

		clocks = <&aoss_qmp>;
		clock-names = "apb_pclk";
	};

	turing_dl_cti_2: cti@10984000 {
		compatible = "arm,coresight-cti", "arm,primecell";
		reg = <0x10984000 0x1000>;

		arm,primecell-periphid = <0x000bb922>;
		coresight-name = "coresight-cti-turing_dl_cti_2";

		clocks = <&aoss_qmp>;
		clock-names = "apb_pclk";
	};

	turing_q6_cti: cti@1098b000 {
		compatible = "arm,coresight-cti", "arm,primecell";
		reg = <0x1098b000 0x1000>;

		arm,primecell-periphid = <0x000bb922>;
		coresight-name = "coresight-cti-turing_q6_cti";

		clocks = <&aoss_qmp>;
		clock-names = "apb_pclk";
	};
};

